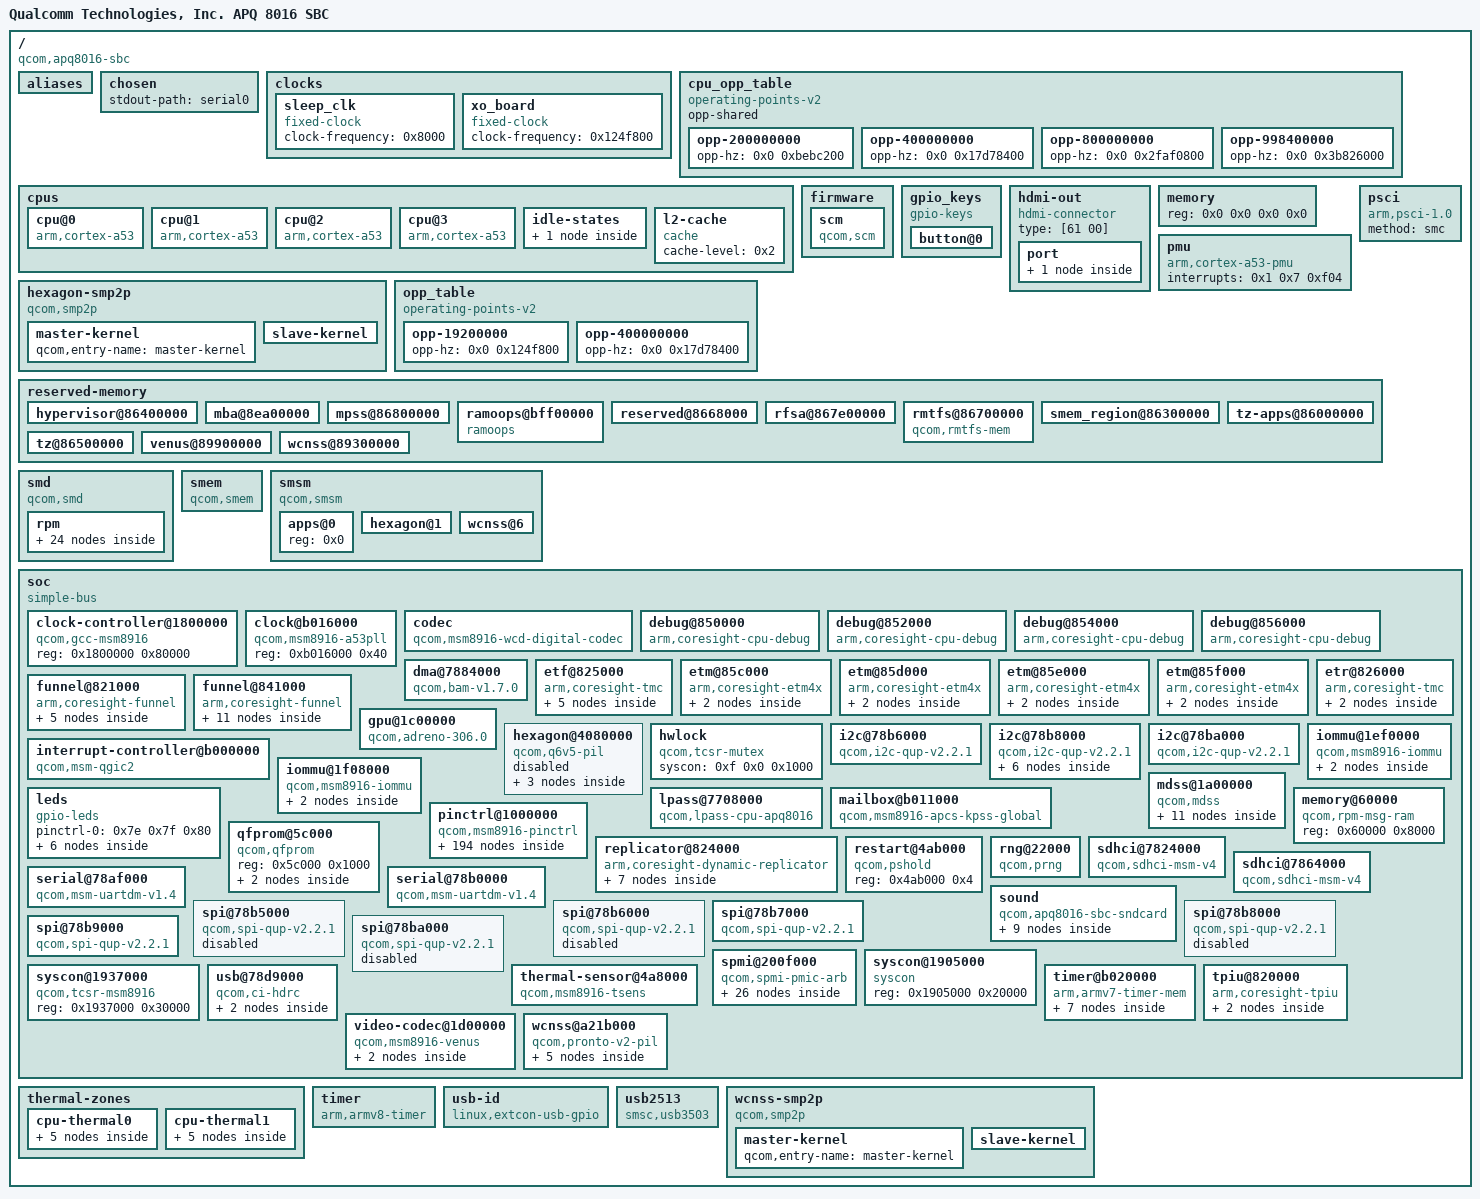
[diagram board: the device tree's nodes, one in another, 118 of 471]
/dts-v1/;

/ {
	#address-cells = <0x2>;
	#size-cells = <0x2>;
	compatible = "qcom,apq8016-sbc", "qcom,apq8016", "qcom,sbc";
	interrupt-parent = <0x1>;
	model = "Qualcomm Technologies, Inc. APQ 8016 SBC";

	__symbols__ {
		CPU0 = "/cpus/cpu@0";
		CPU1 = "/cpus/cpu@1";
		CPU2 = "/cpus/cpu@2";
		CPU3 = "/cpus/cpu@3";
		CPU_SPC = "/cpus/idle-states/spc";
		L2_0 = "/cpus/l2-cache";
		a53pll = "/soc/clock@b016000";
		adv7533_in = "/soc/i2c@78b8000/bridge@39/ports/port@0/endpoint";
		adv7533_int_active = "/soc/pinctrl@1000000/adv533_int_active";
		adv7533_int_suspend = "/soc/pinctrl@1000000/adv7533_int_suspend";
		adv7533_out = "/soc/i2c@78b8000/bridge@39/ports/port@1/endpoint";
		adv7533_switch_active = "/soc/pinctrl@1000000/adv7533_switch_active";
		adv7533_switch_suspend = "/soc/pinctrl@1000000/adv7533_switch_suspend";
		adv_bridge = "/soc/i2c@78b8000/bridge@39";
		apcs = "/soc/mailbox@b011000";
		apps_iommu = "/soc/iommu@1ef0000";
		apps_smsm = "/smsm/apps@0";
		blsp1_uart1 = "/soc/serial@78af000";
		blsp1_uart1_default = "/soc/pinctrl@1000000/blsp1_uart1_default";
		blsp1_uart1_sleep = "/soc/pinctrl@1000000/blsp1_uart1_sleep";
		blsp1_uart2 = "/soc/serial@78b0000";
		blsp1_uart2_default = "/soc/pinctrl@1000000/blsp1_uart2_default";
		blsp1_uart2_sleep = "/soc/pinctrl@1000000/blsp1_uart2_sleep";
		blsp_dma = "/soc/dma@7884000";
		blsp_i2c2 = "/soc/i2c@78b6000";
		blsp_i2c4 = "/soc/i2c@78b8000";
		blsp_i2c6 = "/soc/i2c@78ba000";
		blsp_spi1 = "/soc/spi@78b5000";
		blsp_spi2 = "/soc/spi@78b6000";
		blsp_spi3 = "/soc/spi@78b7000";
		blsp_spi4 = "/soc/spi@78b8000";
		blsp_spi5 = "/soc/spi@78b9000";
		blsp_spi6 = "/soc/spi@78ba000";
		cdc_dmic_lines_act = "/soc/pinctrl@1000000/cdc-dmic-lines/dmic_lines_on";
		cdc_dmic_lines_sus = "/soc/pinctrl@1000000/cdc-dmic-lines/dmic_lines_off";
		cdc_pdm_lines_act = "/soc/pinctrl@1000000/cdc-pdm-lines/pdm_lines_on";
		cdc_pdm_lines_sus = "/soc/pinctrl@1000000/cdc-pdm-lines/pdm_lines_off";
		cpu_alert0 = "/thermal-zones/cpu-thermal0/trips/trip0";
		cpu_alert1 = "/thermal-zones/cpu-thermal1/trips/trip0";
		cpu_crit0 = "/thermal-zones/cpu-thermal0/trips/trip1";
		cpu_crit1 = "/thermal-zones/cpu-thermal1/trips/trip1";
		cpu_opp_table = "/cpu_opp_table";
		dsi0 = "/soc/mdss@1a00000/dsi@1a98000";
		dsi0_in = "/soc/mdss@1a00000/dsi@1a98000/ports/port@0/endpoint";
		dsi0_out = "/soc/mdss@1a00000/dsi@1a98000/ports/port@1/endpoint";
		dsi_phy0 = "/soc/mdss@1a00000/dsi-phy@1a98300";
		etf_in = "/soc/etf@825000/ports/port@0/endpoint";
		etf_out = "/soc/etf@825000/ports/port@1/endpoint";
		etm0_out = "/soc/etm@85c000/port/endpoint";
		etm1_out = "/soc/etm@85d000/port/endpoint";
		etm2_out = "/soc/etm@85e000/port/endpoint";
		etm3_out = "/soc/etm@85f000/port/endpoint";
		etr_in = "/soc/etr@826000/port/endpoint";
		ext_mclk_tlmm_lines_act = "/soc/pinctrl@1000000/ext-mclk-tlmm-lines/mclk_lines_on";
		ext_mclk_tlmm_lines_sus = "/soc/pinctrl@1000000/ext-mclk-tlmm-lines/mclk_lines_off";
		ext_pri_tlmm_lines_act = "/soc/pinctrl@1000000/ext-pri-tlmm-lines/ext_pa_on";
		ext_pri_tlmm_lines_sus = "/soc/pinctrl@1000000/ext-pri-tlmm-lines/ext_pa_off";
		ext_pri_ws_act = "/soc/pinctrl@1000000/ext-pri-ws-line/ext_pa_on";
		ext_pri_ws_sus = "/soc/pinctrl@1000000/ext-pri-ws-line/ext_pa_off";
		ext_sec_tlmm_lines_act = "/soc/pinctrl@1000000/ext-sec-tlmm-lines/tlmm_lines_on";
		ext_sec_tlmm_lines_sus = "/soc/pinctrl@1000000/ext-sec-tlmm-lines/tlmm_lines_off";
		funnel0_in4 = "/soc/funnel@821000/ports/port@4/endpoint";
		funnel0_out = "/soc/funnel@821000/ports/port@8/endpoint";
		funnel1_in0 = "/soc/funnel@841000/ports/port@0/endpoint";
		funnel1_in1 = "/soc/funnel@841000/ports/port@1/endpoint";
		funnel1_in2 = "/soc/funnel@841000/ports/port@2/endpoint";
		funnel1_in3 = "/soc/funnel@841000/ports/port@3/endpoint";
		funnel1_out = "/soc/funnel@841000/ports/port@4/endpoint";
		gcc = "/soc/clock-controller@1800000";
		gpu_iommu = "/soc/iommu@1f08000";
		gpu_opp_table = "/opp_table";
		hdmi_con = "/hdmi-out/port/endpoint";
		hexagon_smp2p_in = "/hexagon-smp2p/slave-kernel";
		hexagon_smp2p_out = "/hexagon-smp2p/master-kernel";
		hexagon_smsm = "/smsm/hexagon@1";
		i2c2_default = "/soc/pinctrl@1000000/i2c2_default";
		i2c2_sleep = "/soc/pinctrl@1000000/i2c2_sleep";
		i2c4_default = "/soc/pinctrl@1000000/i2c4_default";
		i2c4_sleep = "/soc/pinctrl@1000000/i2c4_sleep";
		i2c6_default = "/soc/pinctrl@1000000/i2c6_default";
		i2c6_sleep = "/soc/pinctrl@1000000/i2c6_sleep";
		intc = "/soc/interrupt-controller@b000000";
		lpass = "/soc/lpass@7708000";
		lpass_codec = "/soc/codec";
		ls_exp_gpio_f = "/soc/spmi@200f000/pm8916@0/mpps@a000/pm8916_mpp4";
		mba_mem = "/reserved-memory/mba@8ea00000";
		mdp = "/soc/mdss@1a00000/mdp@1a01000";
		mdp5_intf1_out = "/soc/mdss@1a00000/mdp@1a01000/ports/port@0/endpoint";
		mdss = "/soc/mdss@1a00000";
		mpss_mem = "/reserved-memory/mpss@86800000";
		msm_key_volp_n_default = "/soc/pinctrl@1000000/msm_key_volp_n_default";
		msmgpio = "/soc/pinctrl@1000000";
		msmgpio_leds = "/soc/pinctrl@1000000/msmgpio_leds";
		otg = "/soc/usb@78d9000";
		pm8916_0 = "/soc/spmi@200f000/pm8916@0";
		pm8916_1 = "/soc/spmi@200f000/pm8916@1";
		pm8916_gpios = "/soc/spmi@200f000/pm8916@0/gpios@c000";
		pm8916_gpios_leds = "/soc/spmi@200f000/pm8916@0/gpios@c000/pm8916_gpios_leds";
		pm8916_l1 = "/smd/rpm/rpm_requests/pm8916-regulators/l1";
		pm8916_l10 = "/smd/rpm/rpm_requests/pm8916-regulators/l10";
		pm8916_l11 = "/smd/rpm/rpm_requests/pm8916-regulators/l11";
		pm8916_l12 = "/smd/rpm/rpm_requests/pm8916-regulators/l12";
		pm8916_l13 = "/smd/rpm/rpm_requests/pm8916-regulators/l13";
		pm8916_l14 = "/smd/rpm/rpm_requests/pm8916-regulators/l14";
		pm8916_l15 = "/smd/rpm/rpm_requests/pm8916-regulators/l15";
		pm8916_l16 = "/smd/rpm/rpm_requests/pm8916-regulators/l16";
		pm8916_l17 = "/smd/rpm/rpm_requests/pm8916-regulators/l17";
		pm8916_l18 = "/smd/rpm/rpm_requests/pm8916-regulators/l18";
		pm8916_l2 = "/smd/rpm/rpm_requests/pm8916-regulators/l2";
		pm8916_l3 = "/smd/rpm/rpm_requests/pm8916-regulators/l3";
		pm8916_l4 = "/smd/rpm/rpm_requests/pm8916-regulators/l4";
		pm8916_l5 = "/smd/rpm/rpm_requests/pm8916-regulators/l5";
		pm8916_l6 = "/smd/rpm/rpm_requests/pm8916-regulators/l6";
		pm8916_l7 = "/smd/rpm/rpm_requests/pm8916-regulators/l7";
		pm8916_l8 = "/smd/rpm/rpm_requests/pm8916-regulators/l8";
		pm8916_l9 = "/smd/rpm/rpm_requests/pm8916-regulators/l9";
		pm8916_mpps = "/soc/spmi@200f000/pm8916@0/mpps@a000";
		pm8916_mpps_leds = "/soc/spmi@200f000/pm8916@0/mpps@a000/pm8916_mpps_leds";
		pm8916_s1 = "/smd/rpm/rpm_requests/pm8916-regulators/s1";
		pm8916_s3 = "/smd/rpm/rpm_requests/pm8916-regulators/s3";
		pm8916_s4 = "/smd/rpm/rpm_requests/pm8916-regulators/s4";
		pm8916_temp = "/soc/spmi@200f000/pm8916@0/temp-alarm@2400";
		pm8916_vadc = "/soc/spmi@200f000/pm8916@0/vadc@3100";
		pronto = "/soc/wcnss@a21b000";
		qfprom = "/soc/qfprom@5c000";
		replicator_in = "/soc/replicator@824000/ports/port@2/endpoint";
		replicator_out0 = "/soc/replicator@824000/ports/port@0/endpoint";
		replicator_out1 = "/soc/replicator@824000/ports/port@1/endpoint";
		rpm_msg_ram = "/soc/memory@60000";
		rpmcc = "/smd/rpm/rpm_requests/qcom,rpmcc";
		scm = "/firmware/scm";
		sdc1_clk_off = "/soc/pinctrl@1000000/pmx_sdc1_clk/clk_off";
		sdc1_clk_on = "/soc/pinctrl@1000000/pmx_sdc1_clk/clk_on";
		sdc1_cmd_off = "/soc/pinctrl@1000000/pmx_sdc1_cmd/cmd_off";
		sdc1_cmd_on = "/soc/pinctrl@1000000/pmx_sdc1_cmd/cmd_on";
		sdc1_data_off = "/soc/pinctrl@1000000/pmx_sdc1_data/data_off";
		sdc1_data_on = "/soc/pinctrl@1000000/pmx_sdc1_data/data_on";
		sdc2_cd_off = "/soc/pinctrl@1000000/pmx_sdc2_cd_pin/cd_off";
		sdc2_cd_on = "/soc/pinctrl@1000000/pmx_sdc2_cd_pin/cd_on";
		sdc2_clk_off = "/soc/pinctrl@1000000/pmx_sdc2_clk/clk_off";
		sdc2_clk_on = "/soc/pinctrl@1000000/pmx_sdc2_clk/clk_on";
		sdc2_cmd_off = "/soc/pinctrl@1000000/pmx_sdc2_cmd/cmd_off";
		sdc2_cmd_on = "/soc/pinctrl@1000000/pmx_sdc2_cmd/cmd_on";
		sdc2_data_off = "/soc/pinctrl@1000000/pmx_sdc2_data/data_off";
		sdc2_data_on = "/soc/pinctrl@1000000/pmx_sdc2_data/data_on";
		sdhc_1 = "/soc/sdhci@7824000";
		sdhc_2 = "/soc/sdhci@7864000";
		sleep_clk = "/clocks/sleep_clk";
		smd_rpm_regulators = "/smd/rpm/rpm_requests/pm8916-regulators";
		smem_mem = "/reserved-memory/smem_region@86300000";
		soc = "/soc";
		sound = "/soc/sound";
		spi1_default = "/soc/pinctrl@1000000/spi1_default";
		spi1_sleep = "/soc/pinctrl@1000000/spi1_sleep";
		spi2_default = "/soc/pinctrl@1000000/spi2_default";
		spi2_sleep = "/soc/pinctrl@1000000/spi2_sleep";
		spi3_default = "/soc/pinctrl@1000000/spi3_default";
		spi3_sleep = "/soc/pinctrl@1000000/spi3_sleep";
		spi4_default = "/soc/pinctrl@1000000/spi4_default";
		spi4_sleep = "/soc/pinctrl@1000000/spi4_sleep";
		spi5_default = "/soc/pinctrl@1000000/spi5_default";
		spi5_sleep = "/soc/pinctrl@1000000/spi5_sleep";
		spi6_default = "/soc/pinctrl@1000000/spi6_default";
		spi6_sleep = "/soc/pinctrl@1000000/spi6_sleep";
		spmi_bus = "/soc/spmi@200f000";
		tcsr = "/soc/syscon@1937000";
		tcsr_mutex = "/soc/hwlock";
		tcsr_mutex_regs = "/soc/syscon@1905000";
		tpiu_in = "/soc/tpiu@820000/port/endpoint";
		tsens = "/soc/thermal-sensor@4a8000";
		tsens_caldata = "/soc/qfprom@5c000/caldata@d0";
		tsens_calsel = "/soc/qfprom@5c000/calsel@ec";
		usb_hs_phy = "/soc/usb@78d9000/ulpi/phy";
		usb_hub_reset_pm = "/soc/spmi@200f000/pm8916@0/gpios@c000/usb_hub_reset_pm";
		usb_id = "/usb-id";
		usb_id_default = "/soc/pinctrl@1000000/usb-id-default";
		usb_sw_sel_pm = "/soc/spmi@200f000/pm8916@0/gpios@c000/usb_sw_sel_pm";
		venus = "/soc/video-codec@1d00000";
		venus_mem = "/reserved-memory/venus@89900000";
		wcd_codec = "/soc/spmi@200f000/pm8916@1/codec@f000";
		wcnss_mem = "/reserved-memory/wcnss@89300000";
		wcnss_pin_a = "/soc/pinctrl@1000000/wcnss-active";
		wcnss_smp2p_in = "/wcnss-smp2p/slave-kernel";
		wcnss_smp2p_out = "/wcnss-smp2p/master-kernel";
		wcnss_smsm = "/smsm/wcnss@6";
		xo_board = "/clocks/xo_board";
	};

	aliases {
		i2c0 = "/soc/i2c@78b6000";
		i2c1 = "/soc/i2c@78ba000";
		i2c3 = "/soc/i2c@78b8000";
		sdhc1 = "/soc/sdhci@7824000";
		sdhc2 = "/soc/sdhci@7864000";
		serial0 = "/soc/serial@78b0000";
		serial1 = "/soc/serial@78af000";
		spi0 = "/soc/spi@78b9000";
		spi1 = "/soc/spi@78b7000";
		usid0 = "/soc/spmi@200f000/pm8916@0";
	};

	chosen {
		stdout-path = "serial0";
	};

	clocks {

		sleep_clk {
			#clock-cells = <0x0>;
			clock-frequency = <0x8000>;
			compatible = "fixed-clock";
			linux,phandle = <0x93>;
			phandle = <0x93>;
		};

		xo_board {
			#clock-cells = <0x0>;
			clock-frequency = <0x124f800>;
			compatible = "fixed-clock";
			linux,phandle = <0x32>;
			phandle = <0x32>;
		};
	};

	cpu_opp_table {
		compatible = "operating-points-v2";
		linux,phandle = <0x5>;
		opp-shared;
		phandle = <0x5>;

		opp-200000000 {
			opp-hz = <0x0 0xbebc200>;
		};

		opp-400000000 {
			opp-hz = <0x0 0x17d78400>;
		};

		opp-800000000 {
			opp-hz = <0x0 0x2faf0800>;
		};

		opp-998400000 {
			opp-hz = <0x0 0x3b826000>;
		};
	};

	cpus {
		#address-cells = <0x1>;
		#size-cells = <0x0>;

		cpu@0 {
			#cooling-cells = <0x2>;
			clocks = <0x4>;
			compatible = "arm,cortex-a53", "arm,armv8";
			cpu-idle-states = <0x3>;
			device_type = "cpu";
			enable-method = "psci";
			linux,phandle = <0x8>;
			next-level-cache = <0x2>;
			operating-points-v2 = <0x5>;
			phandle = <0x8>;
			reg = <0x0>;
		};

		cpu@1 {
			#cooling-cells = <0x2>;
			clocks = <0x4>;
			compatible = "arm,cortex-a53", "arm,armv8";
			cpu-idle-states = <0x3>;
			device_type = "cpu";
			enable-method = "psci";
			linux,phandle = <0x76>;
			next-level-cache = <0x2>;
			operating-points-v2 = <0x5>;
			phandle = <0x76>;
			reg = <0x1>;
		};

		cpu@2 {
			#cooling-cells = <0x2>;
			clocks = <0x4>;
			compatible = "arm,cortex-a53", "arm,armv8";
			cpu-idle-states = <0x3>;
			device_type = "cpu";
			enable-method = "psci";
			linux,phandle = <0x77>;
			next-level-cache = <0x2>;
			operating-points-v2 = <0x5>;
			phandle = <0x77>;
			reg = <0x2>;
		};

		cpu@3 {
			#cooling-cells = <0x2>;
			clocks = <0x4>;
			compatible = "arm,cortex-a53", "arm,armv8";
			cpu-idle-states = <0x3>;
			device_type = "cpu";
			enable-method = "psci";
			linux,phandle = <0x78>;
			next-level-cache = <0x2>;
			operating-points-v2 = <0x5>;
			phandle = <0x78>;
			reg = <0x3>;
		};

		idle-states {

			spc {
				arm,psci-suspend-param = <0x40000002>;
				compatible = "arm,idle-state";
				entry-latency-us = <0x82>;
				exit-latency-us = <0x96>;
				linux,phandle = <0x3>;
				local-timer-stop;
				min-residency-us = <0x7d0>;
				phandle = <0x3>;
			};
		};

		l2-cache {
			cache-level = <0x2>;
			compatible = "cache";
			linux,phandle = <0x2>;
			phandle = <0x2>;
		};
	};

	firmware {

		scm {
			#reset-cells = <0x1>;
			clock-names = "core", "bus", "iface";
			clocks = <0xd 0x68 0xd 0x67 0xd 0x66>;
			compatible = "qcom,scm";
			linux,phandle = <0x5b>;
			phandle = <0x5b>;
			qcom,dload-mode = <0xe 0x6100>;
		};
	};

	gpio_keys {
		#address-cells = <0x1>;
		#size-cells = <0x0>;
		autorepeat;
		compatible = "gpio-keys";
		pinctrl-0 = <0x90>;
		pinctrl-names = "default";

		button@0 {
			gpios = <0x26 0x6b 0x1>;
			label = "Volume Up";
			linux,code = <0x73>;
		};
	};

	hdmi-out {
		compatible = "hdmi-connector";
		type = [61 00];

		port {

			endpoint {
				linux,phandle = <0x2f>;
				phandle = <0x2f>;
				remote-endpoint = <0x8f>;
			};
		};
	};

	hexagon-smp2p {
		compatible = "qcom,smp2p";
		interrupts = <0x0 0x1b 0x1>;
		qcom,ipc = <0x4 0x8 0xe>;
		qcom,local-pid = <0x0>;
		qcom,remote-pid = <0x1>;
		qcom,smem = <0x1b3 0x1ac>;

		master-kernel {
			#qcom,smem-state-cells = <0x1>;
			linux,phandle = <0x5a>;
			phandle = <0x5a>;
			qcom,entry-name = "master-kernel";
		};

		slave-kernel {
			#interrupt-cells = <0x2>;
			interrupt-controller;
			linux,phandle = <0x59>;
			phandle = <0x59>;
			qcom,entry-name = "slave-kernel";
		};
	};

	memory {
		device_type = "memory";
		reg = <0x0 0x0 0x0 0x0>;
	};

	opp_table {
		compatible = "operating-points-v2";
		linux,phandle = <0x50>;
		phandle = <0x50>;

		opp-19200000 {
			opp-hz = <0x0 0x124f800>;
		};

		opp-400000000 {
			opp-hz = <0x0 0x17d78400>;
		};
	};

	pmu {
		compatible = "arm,cortex-a53-pmu";
		interrupts = <0x1 0x7 0xf04>;
	};

	psci {
		compatible = "arm,psci-1.0";
		method = "smc";
	};

	reserved-memory {
		#address-cells = <0x2>;
		#size-cells = <0x2>;
		ranges;

		hypervisor@86400000 {
			no-map;
			reg = <0x0 0x86400000 0x0 0x100000>;
		};

		mba@8ea00000 {
			linux,phandle = <0x5e>;
			no-map;
			phandle = <0x5e>;
			reg = <0x0 0x8ea00000 0x0 0x100000>;
		};

		mpss@86800000 {
			linux,phandle = <0x5f>;
			no-map;
			phandle = <0x5f>;
			reg = <0x0 0x86800000 0x0 0x2b00000>;
		};

		ramoops@bff00000 {
			compatible = "ramoops";
			console-size = <0x20000>;
			ftrace-size = <0x20000>;
			record-size = <0x20000>;
			reg = <0x0 0xbff00000 0x0 0x100000>;
		};

		reserved@8668000 {
			no-map;
			reg = <0x0 0x86680000 0x0 0x80000>;
		};

		rfsa@867e00000 {
			no-map;
			reg = <0x0 0x867e0000 0x0 0x20000>;
		};

		rmtfs@86700000 {
			compatible = "qcom,rmtfs-mem";
			no-map;
			qcom,client-id = <0x1>;
			reg = <0x0 0x86700000 0x0 0xe0000>;
		};

		smem_region@86300000 {
			linux,phandle = <0xa>;
			no-map;
			phandle = <0xa>;
			reg = <0x0 0x86300000 0x0 0x100000>;
		};

		tz-apps@86000000 {
			no-map;
			reg = <0x0 0x86000000 0x0 0x300000>;
		};

		tz@86500000 {
			no-map;
			reg = <0x0 0x86500000 0x0 0x180000>;
		};

		venus@89900000 {
			linux,phandle = <0x7d>;
			no-map;
			phandle = <0x7d>;
			reg = <0x0 0x89900000 0x0 0x600000>;
		};

		wcnss@89300000 {
			linux,phandle = <0x60>;
			no-map;
			phandle = <0x60>;
			reg = <0x0 0x89300000 0x0 0x600000>;
		};
	};

	smd {
		compatible = "qcom,smd";

		rpm {
			interrupts = <0x0 0xa8 0x1>;
			qcom,ipc = <0x4 0x8 0x0>;
			qcom,smd-edge = <0xf>;

			rpm_requests {
				compatible = "qcom,rpm-msm8916";
				qcom,smd-channels = "rpm_requests";

				pm8916-regulators {
					compatible = "qcom,rpm-pm8916-regulators";
					linux,phandle = <0xb1>;
					phandle = <0xb1>;
					vdd_l1_l2_l3-supply = <0x64>;
					vdd_l4_l5_l6-supply = <0x8d>;
					vdd_l5-supply = <0x64>;
					vdd_l7-supply = <0x8d>;

					l1 {
						linux,phandle = <0xb2>;
						phandle = <0xb2>;
						regulator-max-microvolt = <0x174508>;
						regulator-min-microvolt = <0x5b8d8>;
					};

					l10 {
						linux,phandle = <0xb4>;
						phandle = <0xb4>;
						regulator-max-microvolt = <0x32eb28>;
						regulator-min-microvolt = <0x1ab3f0>;
					};

					l11 {
						linux,phandle = <0x3b>;
						phandle = <0x3b>;
						regulator-allow-set-load;
						regulator-max-microvolt = <0x32eb28>;
						regulator-min-microvolt = <0x1ab3f0>;
						regulator-system-load = <0x30d40>;
					};

					l12 {
						linux,phandle = <0x3c>;
						phandle = <0x3c>;
						regulator-max-microvolt = <0x32eb28>;
						regulator-min-microvolt = <0x1ab3f0>;
					};

					l13 {
						linux,phandle = <0x4a>;
						phandle = <0x4a>;
						regulator-max-microvolt = <0x32eb28>;
						regulator-min-microvolt = <0x1ab3f0>;
					};

					l14 {
						linux,phandle = <0xb5>;
						phandle = <0xb5>;
						regulator-max-microvolt = <0x32eb28>;
						regulator-min-microvolt = <0x1ab3f0>;
					};

					l15 {
						linux,phandle = <0xb6>;
						phandle = <0xb6>;
						regulator-always-on;
						regulator-max-microvolt = <0x32eb28>;
						regulator-min-microvolt = <0x1ab3f0>;
					};

					l16 {
						linux,phandle = <0xb7>;
						phandle = <0xb7>;
						regulator-max-microvolt = <0x32eb28>;
						regulator-min-microvolt = <0x1ab3f0>;
					};

					l17 {
						linux,phandle = <0x29>;
						phandle = <0x29>;
						regulator-max-microvolt = <0x325aa0>;
						regulator-min-microvolt = <0x325aa0>;
					};

					l18 {
						linux,phandle = <0xb8>;
						phandle = <0xb8>;
						regulator-max-microvolt = <0x32eb28>;
						regulator-min-microvolt = <0x1ab3f0>;
					};

					l2 {
						linux,phandle = <0x56>;
						phandle = <0x56>;
						regulator-max-microvolt = <0x124f80>;
						regulator-min-microvolt = <0x124f80>;
					};

					l3 {
						linux,phandle = <0x5d>;
						phandle = <0x5d>;
						regulator-max-microvolt = <0x174508>;
						regulator-min-microvolt = <0x5b8d8>;
					};

					l4 {
						linux,phandle = <0xb3>;
						phandle = <0xb3>;
						regulator-max-microvolt = <0x32eb28>;
						regulator-min-microvolt = <0x1ab3f0>;
					};

					l5 {
						linux,phandle = <0x34>;
						phandle = <0x34>;
						regulator-max-microvolt = <0x32eb28>;
						regulator-min-microvolt = <0x1ab3f0>;
					};

					l6 {
						linux,phandle = <0x28>;
						phandle = <0x28>;
						regulator-max-microvolt = <0x1b7740>;
						regulator-min-microvolt = <0x1b7740>;
					};

					l7 {
						linux,phandle = <0x49>;
						phandle = <0x49>;
						regulator-max-microvolt = <0x32eb28>;
						regulator-min-microvolt = <0x1ab3f0>;
					};

					l8 {
						linux,phandle = <0x33>;
						phandle = <0x33>;
						regulator-max-microvolt = <0x32eb28>;
						regulator-min-microvolt = <0x1ab3f0>;
					};

					l9 {
						linux,phandle = <0x65>;
						phandle = <0x65>;
						regulator-max-microvolt = <0x32eb28>;
						regulator-min-microvolt = <0x1ab3f0>;
					};

					s1 {
						linux,phandle = <0x5c>;
						phandle = <0x5c>;
						regulator-max-microvolt = <0x17d590>;
						regulator-min-microvolt = <0x5b8d8>;
					};

					s3 {
						linux,phandle = <0x64>;
						phandle = <0x64>;
						regulator-max-microvolt = <0x17d590>;
						regulator-min-microvolt = <0x5b8d8>;
					};

					s4 {
						linux,phandle = <0x8d>;
						phandle = <0x8d>;
						regulator-always-on;
						regulator-boot-on;
						regulator-max-microvolt = <0x1b7740>;
						regulator-min-microvolt = <0x1b7740>;
					};
				};

				qcom,rpmcc {
					#clock-cells = <0x1>;
					compatible = "qcom,rpmcc-msm8916";
					linux,phandle = <0x27>;
					phandle = <0x27>;
				};
			};
		};
	};

	smem {
		compatible = "qcom,smem";
		hwlocks = <0xc 0x3>;
		memory-region = <0xa>;
		qcom,rpm-msg-ram = <0xb>;
	};

	smsm {
		#address-cells = <0x1>;
		#size-cells = <0x0>;
		compatible = "qcom,smsm";
		qcom,ipc-1 = <0x4 0x8 0xd>;
		qcom,ipc-3 = <0x4 0x8 0x13>;

		apps@0 {
			#qcom,smem-state-cells = <0x1>;
			linux,phandle = <0x67>;
			phandle = <0x67>;
			reg = <0x0>;
		};

		hexagon@1 {
			#interrupt-cells = <0x2>;
			interrupt-controller;
			interrupts = <0x0 0x1a 0x1>;
			linux,phandle = <0xb9>;
			phandle = <0xb9>;
			reg = <0x1>;
		};

		wcnss@6 {
			#interrupt-cells = <0x2>;
			interrupt-controller;
			interrupts = <0x0 0x90 0x1>;
			linux,phandle = <0xba>;
			phandle = <0xba>;
			reg = <0x6>;
		};
	};

	soc {
		#address-cells = <0x1>;
		#size-cells = <0x1>;
		compatible = "simple-bus";
		linux,phandle = <0x94>;
		phandle = <0x94>;
		ranges = <0x0 0x0 0x0 0xffffffff>;

		clock-controller@1800000 {
			#clock-cells = <0x1>;
			#power-domain-cells = <0x1>;
			#reset-cells = <0x1>;
			compatible = "qcom,gcc-msm8916";
			linux,phandle = <0xd>;
			phandle = <0xd>;
			reg = <0x1800000 0x80000>;
		};

		clock@b016000 {
			#clock-cells = <0x0>;
			compatible = "qcom,msm8916-a53pll";
			linux,phandle = <0x13>;
			phandle = <0x13>;
			reg = <0xb016000 0x40>;
		};

		codec {
			#sound-dai-cells = <0x1>;
			clock-names = "ahbix-clk", "mclk";
			clocks = <0xd 0x9a 0xd 0x9f>;
			compatible = "qcom,msm8916-wcd-digital-codec";
			linux,phandle = <0x8b>;
			phandle = <0x8b>;
			reg = <0x771c000 0x400>;
			status = "okay";
		};

		debug@850000 {
			clock-names = "apb_pclk";
			clocks = <0x27 0x8>;
			compatible = "arm,coresight-cpu-debug", "arm,primecell";
			cpu = <0x8>;
			reg = <0x850000 0x1000>;
		};

		debug@852000 {
			clock-names = "apb_pclk";
			clocks = <0x27 0x8>;
			compatible = "arm,coresight-cpu-debug", "arm,primecell";
			cpu = <0x76>;
			reg = <0x852000 0x1000>;
		};

		debug@854000 {
			clock-names = "apb_pclk";
			clocks = <0x27 0x8>;
			compatible = "arm,coresight-cpu-debug", "arm,primecell";
			cpu = <0x77>;
			reg = <0x854000 0x1000>;
		};

		debug@856000 {
			clock-names = "apb_pclk";
			clocks = <0x27 0x8>;
			compatible = "arm,coresight-cpu-debug", "arm,primecell";
			cpu = <0x78>;
			reg = <0x856000 0x1000>;
		};

		dma@7884000 {
			#dma-cells = <0x1>;
			clock-names = "bam_clk";
			clocks = <0xd 0x36>;
			compatible = "qcom,bam-v1.7.0";
			interrupts = <0x0 0xee 0x4>;
			linux,phandle = <0x10>;
			phandle = <0x10>;
			qcom,ee = <0x0>;
			reg = <0x7884000 0x23000>;
			status = "okay";
		};

		etf@825000 {
			clock-names = "apb_pclk", "atclk";
			clocks = <0x27 0x8 0x27 0x9>;
			compatible = "arm,coresight-tmc", "arm,primecell";
			reg = <0x825000 0x1000>;

			ports {
				#address-cells = <0x1>;
				#size-cells = <0x0>;

				port@0 {
					reg = <0x0>;

					endpoint {
						linux,phandle = <0x6a>;
						phandle = <0x6a>;
						remote-endpoint = <0x6e>;
						slave-mode;
					};
				};

				port@1 {
					reg = <0x0>;

					endpoint {
						linux,phandle = <0x6d>;
						phandle = <0x6d>;
						remote-endpoint = <0x6f>;
					};
				};
			};
		};

		etm@85c000 {
			clock-names = "apb_pclk", "atclk";
			clocks = <0x27 0x8 0x27 0x9>;
			compatible = "arm,coresight-etm4x", "arm,primecell";
			cpu = <0x8>;
			reg = <0x85c000 0x1000>;

			port {

				endpoint {
					linux,phandle = <0x71>;
					phandle = <0x71>;
					remote-endpoint = <0x79>;
				};
			};
		};

		etm@85d000 {
			clock-names = "apb_pclk", "atclk";
			clocks = <0x27 0x8 0x27 0x9>;
			compatible = "arm,coresight-etm4x", "arm,primecell";
			cpu = <0x76>;
			reg = <0x85d000 0x1000>;

			port {

				endpoint {
					linux,phandle = <0x72>;
					phandle = <0x72>;
					remote-endpoint = <0x7a>;
				};
			};
		};

		etm@85e000 {
			clock-names = "apb_pclk", "atclk";
			clocks = <0x27 0x8 0x27 0x9>;
			compatible = "arm,coresight-etm4x", "arm,primecell";
			cpu = <0x77>;
			reg = <0x85e000 0x1000>;

			port {

				endpoint {
					linux,phandle = <0x73>;
					phandle = <0x73>;
					remote-endpoint = <0x7b>;
				};
			};
		};

		etm@85f000 {
			clock-names = "apb_pclk", "atclk";
			clocks = <0x27 0x8 0x27 0x9>;
			compatible = "arm,coresight-etm4x", "arm,primecell";
			cpu = <0x78>;
			reg = <0x85f000 0x1000>;

			port {

				endpoint {
					linux,phandle = <0x74>;
					phandle = <0x74>;
					remote-endpoint = <0x7c>;
				};
			};
		};

		etr@826000 {
			clock-names = "apb_pclk", "atclk";
			clocks = <0x27 0x8 0x27 0x9>;
			compatible = "arm,coresight-tmc", "arm,primecell";
			reg = <0x826000 0x1000>;

			port {

				endpoint {
					linux,phandle = <0x6b>;
					phandle = <0x6b>;
					remote-endpoint = <0x70>;
					slave-mode;
				};
			};
		};

		funnel@821000 {
			clock-names = "apb_pclk", "atclk";
			clocks = <0x27 0x8 0x27 0x9>;
			compatible = "arm,coresight-funnel", "arm,primecell";
			reg = <0x821000 0x1000>;

			ports {
				#address-cells = <0x1>;
				#size-cells = <0x0>;

				port@4 {
					reg = <0x4>;

					endpoint {
						linux,phandle = <0x75>;
						phandle = <0x75>;
						remote-endpoint = <0x69>;
						slave-mode;
					};
				};

				port@8 {
					reg = <0x0>;

					endpoint {
						linux,phandle = <0x6e>;
						phandle = <0x6e>;
						remote-endpoint = <0x6a>;
					};
				};
			};
		};

		funnel@841000 {
			clock-names = "apb_pclk", "atclk";
			clocks = <0x27 0x8 0x27 0x9>;
			compatible = "arm,coresight-funnel", "arm,primecell";
			reg = <0x841000 0x1000>;

			ports {
				#address-cells = <0x1>;
				#size-cells = <0x0>;

				port@0 {
					reg = <0x0>;

					endpoint {
						linux,phandle = <0x79>;
						phandle = <0x79>;
						remote-endpoint = <0x71>;
						slave-mode;
					};
				};

				port@1 {
					reg = <0x1>;

					endpoint {
						linux,phandle = <0x7a>;
						phandle = <0x7a>;
						remote-endpoint = <0x72>;
						slave-mode;
					};
				};

				port@2 {
					reg = <0x2>;

					endpoint {
						linux,phandle = <0x7b>;
						phandle = <0x7b>;
						remote-endpoint = <0x73>;
						slave-mode;
					};
				};

				port@3 {
					reg = <0x3>;

					endpoint {
						linux,phandle = <0x7c>;
						phandle = <0x7c>;
						remote-endpoint = <0x74>;
						slave-mode;
					};
				};

				port@4 {
					reg = <0x0>;

					endpoint {
						linux,phandle = <0x69>;
						phandle = <0x69>;
						remote-endpoint = <0x75>;
					};
				};
			};
		};

		gpu@1c00000 {
			clock-names = "core", "iface", "mem", "mem_iface", "alt_mem_iface", "gfx3d";
			clocks = <0xd 0x76 0xd 0x75 0xd 0x69 0xd 0x8e 0xd 0x8f 0xd 0xe>;
			compatible = "qcom,adreno-306.0", "qcom,adreno";
			interrupt-names = "kgsl_3d0_irq";
			interrupts = <0x0 0x21 0x4>;
			iommus = <0x51 0x1 0x51 0x2>;
			operating-points-v2 = <0x50>;
			power-domains = <0xd 0x5>;
			reg = <0x1c00000 0x20000>;
			reg-names = "kgsl_3d0_reg_memory";
		};

		hexagon@4080000 {
			clock-names = "iface", "bus", "mem", "xo";
			clocks = <0xd 0x74 0xd 0xa0 0xd 0x46 0x32>;
			compatible = "qcom,q6v5-pil";
			cx-supply = <0x5c>;
			interrupt-names = "wdog", "fatal", "ready", "handover", "stop-ack";
			interrupts-extended = <0x1 0x0 0x18 0x1 0x59 0x0 0x0 0x59 0x1 0x0 0x59 0x2 0x0 0x59 0x3 0x0>;
			mx-supply = <0x5d>;
			pll-supply = <0x49>;
			qcom,halt-regs = <0xe 0x18000 0x19000 0x1a000>;
			qcom,smem-state-names = "stop";
			qcom,smem-states = <0x5a 0x0>;
			reg = <0x4080000 0x100 0x4020000 0x40>;
			reg-names = "qdsp6", "rmb";
			reset-names = "mss_restart";
			resets = <0x5b 0x0>;
			status = "disabled";

			mba {
				memory-region = <0x5e>;
			};

			mpss {
				memory-region = <0x5f>;
			};

			smd-edge {
				interrupts = <0x0 0x19 0x1>;
				label = "hexagon";
				qcom,ipc = <0x4 0x8 0xc>;
				qcom,remote-pid = <0x1>;
				qcom,smd-edge = <0x0>;
			};
		};

		hwlock {
			#hwlock-cells = <0x1>;
			compatible = "qcom,tcsr-mutex";
			linux,phandle = <0xc>;
			phandle = <0xc>;
			syscon = <0xf 0x0 0x1000>;
		};

		i2c@78b6000 {
			#address-cells = <0x1>;
			#size-cells = <0x0>;
			clock-names = "iface", "core";
			clocks = <0xd 0x36 0xd 0x3a>;
			compatible = "qcom,i2c-qup-v2.2.1";
			interrupts = <0x0 0x60 0x4>;
			label = "LS-I2C0";
			linux,phandle = <0xa3>;
			phandle = <0xa3>;
			pinctrl-0 = <0x22>;
			pinctrl-1 = <0x23>;
			pinctrl-names = "default", "sleep";
			reg = <0x78b6000 0x500>;
			status = "okay";
		};

		i2c@78b8000 {
			#address-cells = <0x1>;
			#size-cells = <0x0>;
			clock-names = "iface", "core";
			clocks = <0xd 0x36 0xd 0x3e>;
			compatible = "qcom,i2c-qup-v2.2.1";
			interrupts = <0x0 0x62 0x4>;
			label = "HS-I2C2";
			linux,phandle = <0xa4>;
			phandle = <0xa4>;
			pinctrl-0 = <0x24>;
			pinctrl-1 = <0x25>;
			pinctrl-names = "default", "sleep";
			reg = <0x78b8000 0x500>;
			status = "okay";

			bridge@39 {
				#sound-dai-cells = <0x1>;
				adi,dsi-lanes = <0x4>;
				avdd-supply = <0x28>;
				clock-names = "cec";
				clocks = <0x27 0x18>;
				compatible = "adi,adv7533";
				interrupt-parent = <0x26>;
				interrupts = <0x1f 0x2>;
				linux,phandle = <0x8a>;
				pd-gpios = <0x26 0x20 0x0>;
				phandle = <0x8a>;
				pinctrl-0 = <0x2a 0x2b>;
				pinctrl-1 = <0x2c 0x2d>;
				pinctrl-names = "default", "sleep";
				reg = <0x39>;
				status = "okay";
				v1p2-supply = <0x28>;
				v3p3-supply = <0x29>;

				ports {
					#address-cells = <0x1>;
					#size-cells = <0x0>;

					port@0 {
						reg = <0x0>;

						endpoint {
							linux,phandle = <0x58>;
							phandle = <0x58>;
							remote-endpoint = <0x2e>;
						};
					};

					port@1 {
						reg = <0x1>;

						endpoint {
							linux,phandle = <0x8f>;
							phandle = <0x8f>;
							remote-endpoint = <0x2f>;
						};
					};
				};
			};
		};

		i2c@78ba000 {
			#address-cells = <0x1>;
			#size-cells = <0x0>;
			clock-names = "iface", "core";
			clocks = <0xd 0x36 0xd 0x42>;
			compatible = "qcom,i2c-qup-v2.2.1";
			interrupts = <0x0 0x64 0x4>;
			label = "LS-I2C1";
			linux,phandle = <0xa5>;
			phandle = <0xa5>;
			pinctrl-0 = <0x30>;
			pinctrl-1 = <0x31>;
			pinctrl-names = "default", "sleep";
			reg = <0x78ba000 0x500>;
			status = "okay";
		};

		interrupt-controller@b000000 {
			#interrupt-cells = <0x3>;
			compatible = "qcom,msm-qgic2";
			interrupt-controller;
			linux,phandle = <0x1>;
			phandle = <0x1>;
			reg = <0xb000000 0x1000 0xb002000 0x1000>;
		};

		iommu@1ef0000 {
			#address-cells = <0x1>;
			#iommu-cells = <0x1>;
			#size-cells = <0x1>;
			clock-names = "iface", "bus";
			clocks = <0xd 0x81 0xd 0x8b>;
			compatible = "qcom,msm8916-iommu", "qcom,msm-iommu-v1";
			linux,phandle = <0x53>;
			phandle = <0x53>;
			qcom,iommu-secure-id = <0x11>;
			ranges = <0x0 0x1e20000 0x40000>;
			reg = <0x1ef0000 0x3000>;

			iommu-ctx@4000 {
				compatible = "qcom,msm-iommu-v1-ns";
				interrupts = <0x0 0x46 0x4>;
				reg = <0x4000 0x1000>;
			};

			iommu-ctx@5000 {
				compatible = "qcom,msm-iommu-v1-sec";
				interrupts = <0x0 0x46 0x4>;
				reg = <0x5000 0x1000>;
			};
		};

		iommu@1f08000 {
			#address-cells = <0x1>;
			#iommu-cells = <0x1>;
			#size-cells = <0x1>;
			clock-names = "iface", "bus";
			clocks = <0xd 0x81 0xd 0x8c>;
			compatible = "qcom,msm8916-iommu", "qcom,msm-iommu-v1";
			linux,phandle = <0x51>;
			phandle = <0x51>;
			qcom,iommu-secure-id = <0x12>;
			ranges = <0x0 0x1f08000 0x10000>;

			iommu-ctx@1000 {
				compatible = "qcom,msm-iommu-v1-ns";
				interrupts = <0x0 0xf1 0x4>;
				reg = <0x1000 0x1000>;
			};

			iommu-ctx@2000 {
				compatible = "qcom,msm-iommu-v1-ns";
				interrupts = <0x0 0xf2 0x4>;
				reg = <0x2000 0x1000>;
			};
		};

		leds {
			compatible = "gpio-leds";
			pinctrl-0 = <0x7e 0x7f 0x80>;
			pinctrl-names = "default";

			led@1 {
				default-state = "off";
				gpios = <0x26 0x15 0x0>;
				label = "apq8016-sbc:green:user1";
				linux,default-trigger = "heartbeat";
			};

			led@2 {
				default-state = "off";
				gpios = <0x26 0x78 0x0>;
				label = "apq8016-sbc:green:user2";
				linux,default-trigger = "mmc0";
			};

			led@3 {
				default-state = "off";
				gpios = <0x81 0x1 0x0>;
				label = "apq8016-sbc:green:user3";
				linux,default-trigger = "mmc1";
			};

			led@4 {
				default-state = "off";
				gpios = <0x81 0x2 0x0>;
				label = "apq8016-sbc:green:user4";
				linux,default-trigger = "none";
				panic-indicator;
			};

			led@5 {
				default-state = "off";
				gpios = <0x82 0x2 0x0>;
				label = "apq8016-sbc:yellow:wlan";
				linux,default-trigger = "phy0tx";
			};

			led@6 {
				default-state = "off";
				gpios = <0x82 0x3 0x0>;
				label = "apq8016-sbc:blue:bt";
				linux,default-trigger = "bluetooth-power";
			};
		};

		lpass@7708000 {
			#sound-dai-cells = <0x1>;
			clock-names = "ahbix-clk", "pcnoc-mport-clk", "pcnoc-sway-clk", "mi2s-bit-clk0", "mi2s-bit-clk1", "mi2s-bit-clk2", "mi2s-bit-clk3";
			clocks = <0xd 0x9a 0xd 0x96 0xd 0x97 0xd 0x9c 0xd 0x9d 0xd 0x9d 0xd 0x9e>;
			compatible = "qcom,lpass-cpu-apq8016";
			interrupt-names = "lpass-irq-lpaif";
			interrupts = <0x0 0xa0 0x4>;
			linux,phandle = <0x89>;
			phandle = <0x89>;
			reg = <0x7708000 0x10000>;
			reg-names = "lpass-lpaif";
			status = "okay";
		};

		mailbox@b011000 {
			#clock-cells = <0x0>;
			#mbox-cells = <0x1>;
			clocks = <0x13>;
			compatible = "qcom,msm8916-apcs-kpss-global", "syscon";
			linux,phandle = <0x4>;
			phandle = <0x4>;
			reg = <0xb011000 0x1000>;
		};

		mdss@1a00000 {
			#address-cells = <0x1>;
			#interrupt-cells = <0x1>;
			#size-cells = <0x1>;
			clock-names = "iface", "bus", "vsync";
			clocks = <0xd 0x6d 0xd 0x6e 0xd 0x73>;
			compatible = "qcom,mdss";
			interrupt-controller;
			interrupts = <0x0 0x48 0x4>;
			linux,phandle = <0x52>;
			phandle = <0x52>;
			power-domains = <0xd 0x2>;
			ranges;
			reg = <0x1a00000 0x1000 0x1ac8000 0x3000>;
			reg-names = "mdss_phys", "vbif_phys";
			status = "okay";

			dsi-phy@1a98300 {
				#clock-cells = <0x1>;
				#phy-cells = <0x0>;
				clock-names = "iface";
				clocks = <0xd 0x6d>;
				compatible = "qcom,dsi-phy-28nm-lp";
				linux,phandle = <0x55>;
				phandle = <0x55>;
				reg = <0x1a98300 0xd4 0x1a98500 0x280 0x1a98780 0x30>;
				reg-names = "dsi_pll", "dsi_phy", "dsi_phy_regulator";
				status = "okay";
				vddio-supply = <0x28>;
			};

			dsi@1a98000 {
				assigned-clock-parents = <0x55 0x0 0x55 0x1>;
				assigned-clocks = <0xd 0x2b 0xd 0x2e>;
				clock-names = "mdp_core", "iface", "bus", "byte", "pixel", "core";
				clocks = <0xd 0x71 0xd 0x6d 0xd 0x6e 0xd 0x6f 0xd 0x72 0xd 0x70>;
				compatible = "qcom,mdss-dsi-ctrl";
				interrupt-parent = <0x52>;
				interrupts = <0x4 0x0>;
				linux,phandle = <0xae>;
				phandle = <0xae>;
				phy-names = "dsi-phy";
				phys = <0x55>;
				reg = <0x1a98000 0x25c>;
				reg-names = "dsi_ctrl";
				status = "okay";
				vdda-supply = <0x56>;
				vddio-supply = <0x28>;

				ports {
					#address-cells = <0x1>;
					#size-cells = <0x0>;

					port@0 {
						reg = <0x0>;

						endpoint {
							linux,phandle = <0x54>;
							phandle = <0x54>;
							remote-endpoint = <0x57>;
						};
					};

					port@1 {
						reg = <0x1>;

						endpoint {
							data-lanes = <0x0 0x1 0x2 0x3>;
							linux,phandle = <0x2e>;
							phandle = <0x2e>;
							remote-endpoint = <0x58>;
						};
					};
				};
			};

			mdp@1a01000 {
				clock-names = "iface", "bus", "core", "vsync";
				clocks = <0xd 0x6d 0xd 0x6e 0xd 0x71 0xd 0x73>;
				compatible = "qcom,mdp5";
				interrupt-parent = <0x52>;
				interrupts = <0x0 0x0>;
				iommus = <0x53 0x4>;
				linux,phandle = <0xad>;
				phandle = <0xad>;
				reg = <0x1a01000 0x89000>;
				reg-names = "mdp_phys";
				status = "okay";

				ports {
					#address-cells = <0x1>;
					#size-cells = <0x0>;

					port@0 {
						reg = <0x0>;

						endpoint {
							linux,phandle = <0x57>;
							phandle = <0x57>;
							remote-endpoint = <0x54>;
						};
					};
				};
			};
		};

		memory@60000 {
			compatible = "qcom,rpm-msg-ram";
			linux,phandle = <0xb>;
			phandle = <0xb>;
			reg = <0x60000 0x8000>;
		};

		pinctrl@1000000 {
			#gpio-cells = <0x2>;
			#interrupt-cells = <0x2>;
			compatible = "qcom,msm8916-pinctrl";
			gpio-controller;
			gpio-line-names = "[UART0_TX]", "[UART0_RX]", "[UART0_CTS_N]", "[UART0_RTS_N]", "[UART1_TX]", "[UART1_RX]", "[I2C0_SDA]", "[I2C0_SCL]", "[SPI1_DOUT]", "[SPI1_DIN]", "[SPI1_CS]", "[SPI1_SCLK]", "GPIO-B", "GPIO-C", "[I2C3_SDA]", "[I2C3_SCL]", "[SPI0_MOSI]", "[SPI0_MISO]", "[SPI0_CS_N]", "[SPI0_CLK]", "HDMI_HPD_N", "USR_LED_1_CTRL", "[I2C1_SDA]", "[I2C1_SCL]", "GPIO-G", "GPIO-H", "[CSI0_MCLK]", "[CSI1_MCLK]", "GPIO-K", "[I2C2_SDA]", "[I2C2_SCL]", "DSI2HDMI_INT_N", "DSI_SW_SEL_APQ", "GPIO-L", "GPIO-J", "GPIO-I", "GPIO-A", "FORCED_USB_BOOT", "SD_CARD_DET_N", "[WCSS_BT_SSBI]", "[WCSS_WLAN_DATA_2]", "[WCSS_WLAN_DATA_1]", "[WCSS_WLAN_DATA_0]", "[WCSS_WLAN_SET]", "[WCSS_WLAN_CLK]", "[WCSS_FM_SSBI]", "[WCSS_FM_SDI]", "[WCSS_BT_DAT_CTL]", "[WCSS_BT_DAT_STB]", "NC", "NC", "NC", "NC", "NC", "NC", "NC", "NC", "NC", "NC", "NC", "NC", "NC", "NC", "[CDC_PDM0_CLK]", "[CDC_PDM0_SYNC]", "[CDC_PDM0_TX0]", "[CDC_PDM0_RX0]", "[CDC_PDM0_RX1]", "[CDC_PDM0_RX2]", "GPIO-D", "NC", "NC", "NC", "NC", "NC", "NC", "NC", "NC", "NC", "NC", "BOOT_CONFIG_0", "BOOT_CONFIG_1", "BOOT_CONFIG_2", "BOOT_CONFIG_3", "NC", "NC", "BOOT_CONFIG_5", "NC", "NC", "NC", "NC", "NC", "NC", "NC", "NC", "NC", "NC", "NC", "NC", "NC", "NC", "NC", "NC", "NC", "SSBI_GPS", "NC", "NC", "KEY_VOLP_N", "NC", "NC", "[LS_EXP_MI2S_WS]", "NC", "NC", "[LS_EXP_MI2S_SCK]", "[LS_EXP_MI2S_DATA0]", "GPIO-E", "NC", "[DSI2HDMI_MI2S_WS]", "[DSI2HDMI_MI2S_SCK]", "[DSI2HDMI_MI2S_DATA0]", "USR_LED_2_CTRL", "SB_HS_ID";
			interrupt-controller;
			interrupts = <0x0 0xd0 0x4>;
			linux,phandle = <0x26>;
			phandle = <0x26>;
			reg = <0x1000000 0x300000>;

			adv533_int_active {
				linux,phandle = <0x2a>;
				phandle = <0x2a>;

				pinconf {
					bias-disable;
					drive-strength = <0x10>;
					pins = "gpio31";
				};

				pinmux {
					function = "gpio";
					pins = "gpio31";
				};
			};

			adv7533_int_suspend {
				linux,phandle = <0x2c>;
				phandle = <0x2c>;

				pinconf {
					bias-disable;
					drive-strength = <0x2>;
					pins = "gpio31";
				};

				pinmux {
					function = "gpio";
					pins = "gpio31";
				};
			};

			adv7533_switch_active {
				linux,phandle = <0x2b>;
				phandle = <0x2b>;

				pinconf {
					bias-disable;
					drive-strength = <0x10>;
					pins = "gpio32";
				};

				pinmux {
					function = "gpio";
					pins = "gpio32";
				};
			};

			adv7533_switch_suspend {
				linux,phandle = <0x2d>;
				phandle = <0x2d>;

				pinconf {
					bias-disable;
					drive-strength = <0x2>;
					pins = "gpio32";
				};

				pinmux {
					function = "gpio";
					pins = "gpio32";
				};
			};

			blsp1_uart1_default {
				linux,phandle = <0x11>;
				phandle = <0x11>;

				pinconf {
					bias-disable;
					drive-strength = <0x10>;
					pins = "gpio0", "gpio1", "gpio2", "gpio3";
				};

				pinmux {
					function = "blsp_uart1";
					pins = "gpio0", "gpio1", "gpio2", "gpio3";
				};
			};

			blsp1_uart1_sleep {
				linux,phandle = <0x12>;
				phandle = <0x12>;

				pinconf {
					bias-pull-down;
					drive-strength = <0x2>;
					pins = "gpio0", "gpio1", "gpio2", "gpio3";
				};

				pinmux {
					function = "gpio";
					pins = "gpio0", "gpio1", "gpio2", "gpio3";
				};
			};

			blsp1_uart2_default {
				linux,phandle = <0x14>;
				phandle = <0x14>;

				pinconf {
					bias-disable;
					drive-strength = <0x10>;
					pins = "gpio4", "gpio5";
				};

				pinmux {
					function = "blsp_uart2";
					pins = "gpio4", "gpio5";
				};
			};

			blsp1_uart2_sleep {
				linux,phandle = <0x15>;
				phandle = <0x15>;

				pinconf {
					bias-pull-down;
					drive-strength = <0x2>;
					pins = "gpio4", "gpio5";
				};

				pinmux {
					function = "gpio";
					pins = "gpio4", "gpio5";
				};
			};

			cdc-dmic-lines {

				dmic_lines_off {
					linux,phandle = <0x9a>;
					phandle = <0x9a>;

					pinconf {
						bias-disable;
						drive-strength = <0x2>;
						pins = "gpio0", "gpio1";
					};

					pinmux_dmic0_clk {
						function = "dmic0_clk";
						pins = "gpio0";
					};

					pinmux_dmic0_data {
						function = "dmic0_data";
						pins = "gpio1";
					};
				};

				dmic_lines_on {
					linux,phandle = <0x99>;
					phandle = <0x99>;

					pinconf {
						drive-strength = <0x8>;
						pins = "gpio0", "gpio1";
					};

					pinmux_dmic0_clk {
						function = "dmic0_clk";
						pins = "gpio0";
					};

					pinmux_dmic0_data {
						function = "dmic0_data";
						pins = "gpio1";
					};
				};
			};

			cdc-pdm-lines {

				pdm_lines_off {
					linux,phandle = <0x86>;
					phandle = <0x86>;

					pinconf {
						bias-disable;
						drive-strength = <0x2>;
						pins = "gpio63", "gpio64", "gpio65", "gpio66", "gpio67", "gpio68";
					};

					pinmux {
						function = "cdc_pdm0";
						pins = "gpio63", "gpio64", "gpio65", "gpio66", "gpio67", "gpio68";
					};
				};

				pdm_lines_on {
					linux,phandle = <0x83>;
					phandle = <0x83>;

					pinconf {
						bias-pull-none;
						drive-strength = <0x8>;
						pins = "gpio63", "gpio64", "gpio65", "gpio66", "gpio67", "gpio68";
					};

					pinmux {
						function = "cdc_pdm0";
						pins = "gpio63", "gpio64", "gpio65", "gpio66", "gpio67", "gpio68";
					};
				};
			};

			ext-mclk-tlmm-lines {

				mclk_lines_off {
					linux,phandle = <0x88>;
					phandle = <0x88>;

					pinconf {
						bias-disable;
						drive-strength = <0x2>;
						pins = "gpio116";
					};

					pinmux {
						function = "pri_mi2s";
						pins = "gpio116";
					};
				};

				mclk_lines_on {
					linux,phandle = <0x85>;
					phandle = <0x85>;

					pinconf {
						bias-pull-none;
						drive-strength = <0x8>;
						pins = "gpio116";
					};

					pinmux {
						function = "pri_mi2s";
						pins = "gpio116";
					};
				};
			};

			ext-pri-tlmm-lines {

				ext_pa_off {
					linux,phandle = <0x96>;
					phandle = <0x96>;

					pinconf {
						bias-disable;
						drive-strength = <0x2>;
						pins = "gpio113", "gpio114", "gpio115", "gpio116";
					};

					pinmux {
						function = "pri_mi2s";
						pins = "gpio113", "gpio114", "gpio115", "gpio116";
					};
				};

				ext_pa_on {
					linux,phandle = <0x95>;
					phandle = <0x95>;

					pinconf {
						bias-pull-none;
						drive-strength = <0x8>;
						pins = "gpio113", "gpio114", "gpio115", "gpio116";
					};

					pinmux {
						function = "pri_mi2s";
						pins = "gpio113", "gpio114", "gpio115", "gpio116";
					};
				};
			};

			ext-pri-ws-line {

				ext_pa_off {
					linux,phandle = <0x98>;
					phandle = <0x98>;

					pinconf {
						bias-disable;
						drive-strength = <0x2>;
						pins = "gpio110";
					};

					pinmux {
						function = "pri_mi2s_ws";
						pins = "gpio110";
					};
				};

				ext_pa_on {
					linux,phandle = <0x97>;
					phandle = <0x97>;

					pinconf {
						bias-pull-none;
						drive-strength = <0x8>;
						pins = "gpio110";
					};

					pinmux {
						function = "pri_mi2s_ws";
						pins = "gpio110";
					};
				};
			};

			ext-sec-tlmm-lines {

				tlmm_lines_off {
					linux,phandle = <0x87>;
					phandle = <0x87>;

					pinconf {
						bias-disable;
						drive-strength = <0x2>;
						pins = "gpio112", "gpio117", "gpio118", "gpio119";
					};

					pinmux {
						function = "sec_mi2s";
						pins = "gpio112", "gpio117", "gpio118", "gpio119";
					};
				};

				tlmm_lines_on {
					linux,phandle = <0x84>;
					phandle = <0x84>;

					pinconf {
						bias-pull-none;
						drive-strength = <0x8>;
						pins = "gpio112", "gpio117", "gpio118", "gpio119";
					};

					pinmux {
						function = "sec_mi2s";
						pins = "gpio112", "gpio117", "gpio118", "gpio119";
					};
				};
			};

			i2c2_default {
				linux,phandle = <0x22>;
				phandle = <0x22>;

				pinconf {
					bias-disable;
					drive-strength = <0x10>;
					pins = "gpio6", "gpio7";
				};

				pinmux {
					function = "blsp_i2c2";
					pins = "gpio6", "gpio7";
				};
			};

			i2c2_sleep {
				linux,phandle = <0x23>;
				phandle = <0x23>;

				pinconf {
					bias-disable;
					drive-strength = <0x2>;
					pins = "gpio6", "gpio7";
				};

				pinmux {
					function = "gpio";
					pins = "gpio6", "gpio7";
				};
			};

			i2c4_default {
				linux,phandle = <0x24>;
				phandle = <0x24>;

				pinconf {
					bias-disable;
					drive-strength = <0x10>;
					pins = "gpio14", "gpio15";
				};

				pinmux {
					function = "blsp_i2c4";
					pins = "gpio14", "gpio15";
				};
			};

			i2c4_sleep {
				linux,phandle = <0x25>;
				phandle = <0x25>;

				pinconf {
					bias-disable;
					drive-strength = <0x2>;
					pins = "gpio14", "gpio15";
				};

				pinmux {
					function = "gpio";
					pins = "gpio14", "gpio15";
				};
			};

			i2c6_default {
				linux,phandle = <0x30>;
				phandle = <0x30>;

				pinconf {
					bias-disable;
					drive-strength = <0x10>;
					pins = "gpio22", "gpio23";
				};

				pinmux {
					function = "blsp_i2c6";
					pins = "gpio22", "gpio23";
				};
			};

			i2c6_sleep {
				linux,phandle = <0x31>;
				phandle = <0x31>;

				pinconf {
					bias-disable;
					drive-strength = <0x2>;
					pins = "gpio22", "gpio23";
				};

				pinmux {
					function = "gpio";
					pins = "gpio22", "gpio23";
				};
			};

			msm_key_volp_n_default {
				linux,phandle = <0x90>;
				phandle = <0x90>;

				pinconf {
					bias-pull-up;
					drive-strength = <0x8>;
					input-enable;
					pins = "gpio107";
				};

				pinmux {
					function = "gpio";
					pins = "gpio107";
				};
			};

			msmgpio_leds {
				linux,phandle = <0x7e>;
				phandle = <0x7e>;

				pinconf {
					function = "gpio";
					output-low;
					pins = "gpio21", "gpio120";
				};
			};

			pmx_sdc1_clk {

				clk_off {
					linux,phandle = <0x38>;
					phandle = <0x38>;

					pinconf {
						bias-disable;
						drive-strength = <0x2>;
						pins = "sdc1_clk";
					};

					pinmux {
						pins = "sdc1_clk";
					};
				};

				clk_on {
					linux,phandle = <0x35>;
					phandle = <0x35>;

					pinconf {
						bias-disable;
						drive-strength = <0x10>;
						pins = "sdc1_clk";
					};

					pinmux {
						pins = "sdc1_clk";
					};
				};
			};

			pmx_sdc1_cmd {

				cmd_off {
					linux,phandle = <0x39>;
					phandle = <0x39>;

					pinconf {
						bias-pull-up;
						drive-strength = <0x2>;
						pins = "sdc1_cmd";
					};

					pinmux {
						pins = "sdc1_cmd";
					};
				};

				cmd_on {
					linux,phandle = <0x36>;
					phandle = <0x36>;

					pinconf {
						bias-pull-up;
						drive-strength = <0xa>;
						pins = "sdc1_cmd";
					};

					pinmux {
						pins = "sdc1_cmd";
					};
				};
			};

			pmx_sdc1_data {

				data_off {
					linux,phandle = <0x3a>;
					phandle = <0x3a>;

					pinconf {
						bias-pull-up;
						drive-strength = <0x2>;
						pins = "sdc1_data";
					};

					pinmux {
						pins = "sdc1_data";
					};
				};

				data_on {
					linux,phandle = <0x37>;
					phandle = <0x37>;

					pinconf {
						bias-pull-up;
						drive-strength = <0xa>;
						pins = "sdc1_data";
					};

					pinmux {
						pins = "sdc1_data";
					};
				};
			};

			pmx_sdc2_cd_pin {

				cd_off {
					linux,phandle = <0x44>;
					phandle = <0x44>;

					pinconf {
						bias-disable;
						drive-strength = <0x2>;
						pins = "gpio38";
					};

					pinmux {
						function = "gpio";
						pins = "gpio38";
					};
				};

				cd_on {
					linux,phandle = <0x40>;
					phandle = <0x40>;

					pinconf {
						bias-pull-up;
						drive-strength = <0x2>;
						pins = "gpio38";
					};

					pinmux {
						function = "gpio";
						pins = "gpio38";
					};
				};
			};

			pmx_sdc2_clk {

				clk_off {
					linux,phandle = <0x41>;
					phandle = <0x41>;

					pinconf {
						bias-disable;
						drive-strength = <0x2>;
						pins = "sdc2_clk";
					};

					pinmux {
						pins = "sdc2_clk";
					};
				};

				clk_on {
					linux,phandle = <0x3d>;
					phandle = <0x3d>;

					pinconf {
						bias-disable;
						drive-strength = <0x10>;
						pins = "sdc2_clk";
					};

					pinmux {
						pins = "sdc2_clk";
					};
				};
			};

			pmx_sdc2_cmd {

				cmd_off {
					linux,phandle = <0x42>;
					phandle = <0x42>;

					pinconf {
						bias-pull-up;
						drive-strength = <0x2>;
						pins = "sdc2_cmd";
					};

					pinmux {
						pins = "sdc2_cmd";
					};
				};

				cmd_on {
					linux,phandle = <0x3e>;
					phandle = <0x3e>;

					pinconf {
						bias-pull-up;
						drive-strength = <0xa>;
						pins = "sdc2_cmd";
					};

					pinmux {
						pins = "sdc2_cmd";
					};
				};
			};

			pmx_sdc2_data {

				data_off {
					linux,phandle = <0x43>;
					phandle = <0x43>;

					pinconf {
						bias-pull-up;
						drive-strength = <0x2>;
						pins = "sdc2_data";
					};

					pinmux {
						pins = "sdc2_data";
					};
				};

				data_on {
					linux,phandle = <0x3f>;
					phandle = <0x3f>;

					pinconf {
						bias-pull-up;
						drive-strength = <0xa>;
						pins = "sdc2_data";
					};

					pinmux {
						pins = "sdc2_data";
					};
				};
			};

			spi1_default {
				linux,phandle = <0x16>;
				phandle = <0x16>;

				pinconf {
					bias-disable;
					drive-strength = <0xc>;
					pins = "gpio0", "gpio1", "gpio3";
				};

				pinconf_cs {
					bias-disable;
					drive-strength = <0x10>;
					output-high;
					pins = "gpio2";
				};

				pinmux {
					function = "blsp_spi1";
					pins = "gpio0", "gpio1", "gpio3";
				};

				pinmux_cs {
					function = "gpio";
					pins = "gpio2";
				};
			};

			spi1_sleep {
				linux,phandle = <0x17>;
				phandle = <0x17>;

				pinconf {
					bias-pull-down;
					drive-strength = <0x2>;
					pins = "gpio0", "gpio1", "gpio2", "gpio3";
				};

				pinmux {
					function = "gpio";
					pins = "gpio0", "gpio1", "gpio2", "gpio3";
				};
			};

			spi2_default {
				linux,phandle = <0x18>;
				phandle = <0x18>;

				pinconf {
					bias-disable;
					drive-strength = <0xc>;
					pins = "gpio4", "gpio5", "gpio7";
				};

				pinconf_cs {
					bias-disable;
					drive-strength = <0x10>;
					output-high;
					pins = "gpio6";
				};

				pinmux {
					function = "blsp_spi2";
					pins = "gpio4", "gpio5", "gpio7";
				};

				pinmux_cs {
					function = "gpio";
					pins = "gpio6";
				};
			};

			spi2_sleep {
				linux,phandle = <0x19>;
				phandle = <0x19>;

				pinconf {
					bias-pull-down;
					drive-strength = <0x2>;
					pins = "gpio4", "gpio5", "gpio6", "gpio7";
				};

				pinmux {
					function = "gpio";
					pins = "gpio4", "gpio5", "gpio6", "gpio7";
				};
			};

			spi3_default {
				linux,phandle = <0x1a>;
				phandle = <0x1a>;

				pinconf {
					bias-disable;
					drive-strength = <0xc>;
					pins = "gpio8", "gpio9", "gpio11";
				};

				pinconf_cs {
					bias-disable;
					drive-strength = <0x10>;
					output-high;
					pins = "gpio10";
				};

				pinmux {
					function = "blsp_spi3";
					pins = "gpio8", "gpio9", "gpio11";
				};

				pinmux_cs {
					function = "gpio";
					pins = "gpio10";
				};
			};

			spi3_sleep {
				linux,phandle = <0x1b>;
				phandle = <0x1b>;

				pinconf {
					bias-pull-down;
					drive-strength = <0x2>;
					pins = "gpio8", "gpio9", "gpio10", "gpio11";
				};

				pinmux {
					function = "gpio";
					pins = "gpio8", "gpio9", "gpio10", "gpio11";
				};
			};

			spi4_default {
				linux,phandle = <0x1c>;
				phandle = <0x1c>;

				pinconf {
					bias-disable;
					drive-strength = <0xc>;
					pins = "gpio12", "gpio13", "gpio15";
				};

				pinconf_cs {
					bias-disable;
					drive-strength = <0x10>;
					output-high;
					pins = "gpio14";
				};

				pinmux {
					function = "blsp_spi4";
					pins = "gpio12", "gpio13", "gpio15";
				};

				pinmux_cs {
					function = "gpio";
					pins = "gpio14";
				};
			};

			spi4_sleep {
				linux,phandle = <0x1d>;
				phandle = <0x1d>;

				pinconf {
					bias-pull-down;
					drive-strength = <0x2>;
					pins = "gpio12", "gpio13", "gpio14", "gpio15";
				};

				pinmux {
					function = "gpio";
					pins = "gpio12", "gpio13", "gpio14", "gpio15";
				};
			};

			spi5_default {
				linux,phandle = <0x1e>;
				phandle = <0x1e>;

				pinconf {
					bias-disable;
					drive-strength = <0xc>;
					pins = "gpio16", "gpio17", "gpio19";
				};

				pinconf_cs {
					bias-disable;
					drive-strength = <0x10>;
					output-high;
					pins = "gpio18";
				};

				pinmux {
					function = "blsp_spi5";
					pins = "gpio16", "gpio17", "gpio19";
				};

				pinmux_cs {
					function = "gpio";
					pins = "gpio18";
				};
			};

			spi5_sleep {
				linux,phandle = <0x1f>;
				phandle = <0x1f>;

				pinconf {
					bias-pull-down;
					drive-strength = <0x2>;
					pins = "gpio16", "gpio17", "gpio18", "gpio19";
				};

				pinmux {
					function = "gpio";
					pins = "gpio16", "gpio17", "gpio18", "gpio19";
				};
			};

			spi6_default {
				linux,phandle = <0x20>;
				phandle = <0x20>;

				pinconf {
					bias-disable;
					drive-strength = <0xc>;
					pins = "gpio20", "gpio21", "gpio23";
				};

				pinconf_cs {
					bias-disable;
					drive-strength = <0x10>;
					output-high;
					pins = "gpio22";
				};

				pinmux {
					function = "blsp_spi6";
					pins = "gpio20", "gpio21", "gpio23";
				};

				pinmux_cs {
					function = "gpio";
					pins = "gpio22";
				};
			};

			spi6_sleep {
				linux,phandle = <0x21>;
				phandle = <0x21>;

				pinconf {
					bias-pull-down;
					drive-strength = <0x2>;
					pins = "gpio20", "gpio21", "gpio22", "gpio23";
				};

				pinmux {
					function = "gpio";
					pins = "gpio20", "gpio21", "gpio22", "gpio23";
				};
			};

			usb-id-default {
				linux,phandle = <0x8e>;
				phandle = <0x8e>;

				pinconf {
					bias-pull-up;
					drive-strength = <0x8>;
					input-enable;
					pins = "gpio121";
				};

				pinmux {
					function = "gpio";
					pins = "gpio121";
				};
			};

			wcnss-active {
				linux,phandle = <0x63>;
				phandle = <0x63>;

				pinconf {
					bias-pull-up;
					drive-strength = <0x6>;
					pins = "gpio40", "gpio41", "gpio42", "gpio43", "gpio44";
				};

				pinmux {
					function = "wcss_wlan";
					pins = "gpio40", "gpio41", "gpio42", "gpio43", "gpio44";
				};
			};
		};

		qfprom@5c000 {
			#address-cells = <0x1>;
			#size-cells = <0x1>;
			compatible = "qcom,qfprom";
			linux,phandle = <0xac>;
			phandle = <0xac>;
			reg = <0x5c000 0x1000>;

			caldata@d0 {
				linux,phandle = <0x4e>;
				phandle = <0x4e>;
				reg = <0xd0 0x8>;
			};

			calsel@ec {
				linux,phandle = <0x4f>;
				phandle = <0x4f>;
				reg = <0xec 0x4>;
			};
		};

		replicator@824000 {
			clock-names = "apb_pclk", "atclk";
			clocks = <0x27 0x8 0x27 0x9>;
			compatible = "arm,coresight-dynamic-replicator", "arm,primecell";
			reg = <0x824000 0x1000>;

			ports {
				#address-cells = <0x1>;
				#size-cells = <0x0>;

				port@0 {
					reg = <0x0>;

					endpoint {
						linux,phandle = <0x70>;
						phandle = <0x70>;
						remote-endpoint = <0x6b>;
					};
				};

				port@1 {
					reg = <0x1>;

					endpoint {
						linux,phandle = <0x68>;
						phandle = <0x68>;
						remote-endpoint = <0x6c>;
					};
				};

				port@2 {
					reg = <0x0>;

					endpoint {
						linux,phandle = <0x6f>;
						phandle = <0x6f>;
						remote-endpoint = <0x6d>;
						slave-mode;
					};
				};
			};
		};

		restart@4ab000 {
			compatible = "qcom,pshold";
			reg = <0x4ab000 0x4>;
		};

		rng@22000 {
			clock-names = "core";
			clocks = <0xd 0x79>;
			compatible = "qcom,prng";
			reg = <0x22000 0x200>;
		};

		sdhci@7824000 {
			bus-width = <0x8>;
			clock-names = "core", "iface", "xo";
			clocks = <0xd 0x7b 0xd 0x7a 0x32>;
			compatible = "qcom,sdhci-msm-v4";
			interrupt-names = "hc_irq", "pwr_irq";
			interrupts = <0x0 0x7b 0x4 0x0 0x8a 0x4>;
			linux,phandle = <0xa6>;
			mmc-ddr-1_8v;
			non-removable;
			phandle = <0xa6>;
			pinctrl-0 = <0x35 0x36 0x37>;
			pinctrl-1 = <0x38 0x39 0x3a>;
			pinctrl-names = "default", "sleep";
			reg = <0x7824900 0x11c 0x7824000 0x800>;
			reg-names = "hc_mem", "core_mem";
			status = "okay";
			vmmc-supply = <0x33>;
			vqmmc-supply = <0x34>;
		};

		sdhci@7864000 {
			bus-width = <0x4>;
			cd-gpios = <0x26 0x26 0x1>;
			clock-names = "core", "iface", "xo";
			clocks = <0xd 0x7d 0xd 0x7c 0x32>;
			compatible = "qcom,sdhci-msm-v4";
			interrupt-names = "hc_irq", "pwr_irq";
			interrupts = <0x0 0x7d 0x4 0x0 0xdd 0x4>;
			linux,phandle = <0xa7>;
			phandle = <0xa7>;
			pinctrl-0 = <0x3d 0x3e 0x3f 0x40>;
			pinctrl-1 = <0x41 0x42 0x43 0x44>;
			pinctrl-names = "default", "sleep";
			reg = <0x7864900 0x11c 0x7864000 0x800>;
			reg-names = "hc_mem", "core_mem";
			status = "okay";
			vmmc-supply = <0x3b>;
			vqmmc-supply = <0x3c>;
		};

		serial@78af000 {
			clock-names = "core", "iface";
			clocks = <0xd 0x44 0xd 0x36>;
			compatible = "qcom,msm-uartdm-v1.4", "qcom,msm-uartdm";
			dma-names = "rx", "tx";
			dmas = <0x10 0x1 0x10 0x0>;
			interrupts = <0x0 0x6b 0x4>;
			label = "LS-UART0";
			linux,phandle = <0x9b>;
			phandle = <0x9b>;
			pinctrl-0 = <0x11>;
			pinctrl-1 = <0x12>;
			pinctrl-names = "default", "sleep";
			reg = <0x78af000 0x200>;
			status = "okay";
		};

		serial@78b0000 {
			clock-names = "core", "iface";
			clocks = <0xd 0x45 0xd 0x36>;
			compatible = "qcom,msm-uartdm-v1.4", "qcom,msm-uartdm";
			dma-names = "rx", "tx";
			dmas = <0x10 0x3 0x10 0x2>;
			interrupts = <0x0 0x6c 0x4>;
			label = "LS-UART1";
			linux,phandle = <0x9c>;
			phandle = <0x9c>;
			pinctrl-0 = <0x14>;
			pinctrl-1 = <0x15>;
			pinctrl-names = "default", "sleep";
			reg = <0x78b0000 0x200>;
			status = "okay";
		};

		sound {
			compatible = "qcom,apq8016-sbc-sndcard";
			linux,phandle = <0xb0>;
			phandle = <0xb0>;
			pinctrl-0 = <0x83 0x84 0x85>;
			pinctrl-1 = <0x86 0x87 0x88>;
			pinctrl-names = "default", "sleep";
			qcom,audio-routing = "AMIC2", "MIC BIAS Internal2", "AMIC3", "MIC BIAS External1";
			qcom,model = "DB410c";
			reg = <0x7702000 0x4 0x7702004 0x4>;
			reg-names = "mic-iomux", "spkr-iomux";
			status = "okay";

			external-dai-link@0 {
				link-name = "ADV7533";

				codec {
					sound-dai = <0x8a 0x0>;
				};

				cpu {
					sound-dai = <0x89 0x3>;
				};
			};

			internal-codec-capture-dai-link@0 {
				link-name = "WCD-Capture";

				codec {
					sound-dai = <0x8b 0x1 0x8c 0x1>;
				};

				cpu {
					sound-dai = <0x89 0x2>;
				};
			};

			internal-codec-playback-dai-link@0 {
				link-name = "WCD";

				codec {
					sound-dai = <0x8b 0x0 0x8c 0x0>;
				};

				cpu {
					sound-dai = <0x89 0x0>;
				};
			};
		};

		spi@78b5000 {
			#address-cells = <0x1>;
			#size-cells = <0x0>;
			clock-names = "core", "iface";
			clocks = <0xd 0x39 0xd 0x36>;
			compatible = "qcom,spi-qup-v2.2.1";
			dma-names = "rx", "tx";
			dmas = <0x10 0x5 0x10 0x4>;
			interrupts = <0x0 0x5f 0x4>;
			linux,phandle = <0x9d>;
			phandle = <0x9d>;
			pinctrl-0 = <0x16>;
			pinctrl-1 = <0x17>;
			pinctrl-names = "default", "sleep";
			reg = <0x78b5000 0x500>;
			status = "disabled";
		};

		spi@78b6000 {
			#address-cells = <0x1>;
			#size-cells = <0x0>;
			clock-names = "core", "iface";
			clocks = <0xd 0x3b 0xd 0x36>;
			compatible = "qcom,spi-qup-v2.2.1";
			dma-names = "rx", "tx";
			dmas = <0x10 0x7 0x10 0x6>;
			interrupts = <0x0 0x60 0x4>;
			linux,phandle = <0x9e>;
			phandle = <0x9e>;
			pinctrl-0 = <0x18>;
			pinctrl-1 = <0x19>;
			pinctrl-names = "default", "sleep";
			reg = <0x78b6000 0x500>;
			status = "disabled";
		};

		spi@78b7000 {
			#address-cells = <0x1>;
			#size-cells = <0x0>;
			clock-names = "core", "iface";
			clocks = <0xd 0x3d 0xd 0x36>;
			compatible = "qcom,spi-qup-v2.2.1";
			dma-names = "rx", "tx";
			dmas = <0x10 0x9 0x10 0x8>;
			interrupts = <0x0 0x61 0x4>;
			label = "HS-SPI1";
			linux,phandle = <0x9f>;
			phandle = <0x9f>;
			pinctrl-0 = <0x1a>;
			pinctrl-1 = <0x1b>;
			pinctrl-names = "default", "sleep";
			reg = <0x78b7000 0x500>;
			status = "okay";
		};

		spi@78b8000 {
			#address-cells = <0x1>;
			#size-cells = <0x0>;
			clock-names = "core", "iface";
			clocks = <0xd 0x3f 0xd 0x36>;
			compatible = "qcom,spi-qup-v2.2.1";
			dma-names = "rx", "tx";
			dmas = <0x10 0xb 0x10 0xa>;
			interrupts = <0x0 0x62 0x4>;
			linux,phandle = <0xa0>;
			phandle = <0xa0>;
			pinctrl-0 = <0x1c>;
			pinctrl-1 = <0x1d>;
			pinctrl-names = "default", "sleep";
			reg = <0x78b8000 0x500>;
			status = "disabled";
		};

		spi@78b9000 {
			#address-cells = <0x1>;
			#size-cells = <0x0>;
			clock-names = "core", "iface";
			clocks = <0xd 0x41 0xd 0x36>;
			compatible = "qcom,spi-qup-v2.2.1";
			dma-names = "rx", "tx";
			dmas = <0x10 0xd 0x10 0xc>;
			interrupts = <0x0 0x63 0x4>;
			label = "LS-SPI0";
			linux,phandle = <0xa1>;
			phandle = <0xa1>;
			pinctrl-0 = <0x1e>;
			pinctrl-1 = <0x1f>;
			pinctrl-names = "default", "sleep";
			reg = <0x78b9000 0x500>;
			status = "okay";
		};

		spi@78ba000 {
			#address-cells = <0x1>;
			#size-cells = <0x0>;
			clock-names = "core", "iface";
			clocks = <0xd 0x43 0xd 0x36>;
			compatible = "qcom,spi-qup-v2.2.1";
			dma-names = "rx", "tx";
			dmas = <0x10 0xf 0x10 0xe>;
			interrupts = <0x0 0x64 0x4>;
			linux,phandle = <0xa2>;
			phandle = <0xa2>;
			pinctrl-0 = <0x20>;
			pinctrl-1 = <0x21>;
			pinctrl-names = "default", "sleep";
			reg = <0x78ba000 0x500>;
			status = "disabled";
		};

		spmi@200f000 {
			#address-cells = <0x2>;
			#interrupt-cells = <0x4>;
			#size-cells = <0x0>;
			compatible = "qcom,spmi-pmic-arb";
			interrupt-controller;
			interrupt-names = "periph_irq";
			interrupts = <0x0 0xbe 0x4>;
			linux,phandle = <0x4d>;
			phandle = <0x4d>;
			qcom,channel = <0x0>;
			qcom,ee = <0x0>;
			reg = <0x200f000 0x1000 0x2400000 0x400000 0x2c00000 0x400000 0x3800000 0x200000 0x200a000 0x2100>;
			reg-names = "core", "chnls", "obsrvr", "intr", "cnfg";

			pm8916@0 {
				#address-cells = <0x1>;
				#size-cells = <0x0>;
				compatible = "qcom,pm8916", "qcom,spmi-pmic";
				linux,phandle = <0xa8>;
				phandle = <0xa8>;
				reg = <0x0 0x0>;

				gpios@c000 {
					#gpio-cells = <0x2>;
					compatible = "qcom,pm8916-gpio";
					gpio-controller;
					gpio-line-names = "USR_LED_3_CTRL", "USR_LED_4_CTRL", "USB_HUB_RESET_N_PM", "USB_SW_SEL_PM";
					interrupts = <0x0 0xc0 0x0 0x0 0x0 0xc1 0x0 0x0 0x0 0xc2 0x0 0x0 0x0 0xc3 0x0 0x0>;
					linux,phandle = <0x81>;
					phandle = <0x81>;
					reg = <0xc000>;

					pm8916_gpios_leds {
						linux,phandle = <0x7f>;
						phandle = <0x7f>;

						pinconf {
							function = "normal";
							output-low;
							pins = "gpio1", "gpio2";
						};
					};

					usb_hub_reset_pm {
						linux,phandle = <0xa9>;
						phandle = <0xa9>;

						pinconf {
							function = "normal";
							output-low;
							pins = "gpio3";
						};
					};

					usb_sw_sel_pm {
						linux,phandle = <0x47>;
						phandle = <0x47>;

						pinconf {
							function = "normal";
							input-disable;
							output-high;
							pins = "gpio4";
							power-source = <0x0>;
						};
					};
				};

				mpps@a000 {
					#gpio-cells = <0x2>;
					compatible = "qcom,pm8916-mpp";
					gpio-controller;
					gpio-line-names = "VDD_PX_BIAS", "WLAN_LED_CTRL", "BT_LED_CTRL", "GPIO-F";
					interrupts = <0x0 0xa0 0x0 0x0 0x0 0xa1 0x0 0x0 0x0 0xa2 0x0 0x0 0x0 0xa3 0x0 0x0>;
					linux,phandle = <0x82>;
					phandle = <0x82>;
					pinctrl-0 = <0x4b>;
					pinctrl-names = "default";
					reg = <0xa000>;

					pm8916_mpp4 {
						linux,phandle = <0x4b>;
						phandle = <0x4b>;

						pinconf {
							function = "digital";
							output-low;
							pins = "mpp4";
							power-source = <0x3>;
						};
					};

					pm8916_mpps_leds {
						linux,phandle = <0x80>;
						phandle = <0x80>;

						pinconf {
							function = "digital";
							output-low;
							pins = "mpp2", "mpp3";
						};
					};
				};

				pwrkey@800 {
					bias-pull-up;
					compatible = "qcom,pm8941-pwrkey";
					debounce = <0x3d09>;
					interrupts = <0x0 0x8 0x0 0x3>;
					reg = <0x800>;
				};

				rtc@6000 {
					compatible = "qcom,pm8941-rtc";
					interrupts = <0x0 0x61 0x1 0x1>;
					reg = <0x6000>;
					reg-names = "rtc", "alarm";
				};

				temp-alarm@2400 {
					#thermal-sensor-cells = <0x0>;
					compatible = "qcom,spmi-temp-alarm";
					interrupts = <0x0 0x24 0x0 0x1>;
					io-channel-names = "thermal";
					io-channels = <0x4c 0x8>;
					linux,phandle = <0xaa>;
					phandle = <0xaa>;
					reg = <0x2400>;
				};

				vadc@3100 {
					#address-cells = <0x1>;
					#io-channel-cells = <0x1>;
					#size-cells = <0x0>;
					compatible = "qcom,spmi-vadc";
					interrupts = <0x0 0x31 0x0 0x1>;
					linux,phandle = <0x4c>;
					phandle = <0x4c>;
					reg = <0x3100>;

					die_temp {
						reg = <0x8>;
					};

					ref_1250v {
						reg = <0xa>;
					};

					ref_625mv {
						reg = <0x9>;
					};

					ref_gnd {
						reg = <0xe>;
					};

					ref_vdd {
						reg = <0xf>;
					};

					usb_in {
						qcom,pre-scaling = <0x1 0xa>;
						reg = <0x0>;
					};

					vph_pwr {
						qcom,pre-scaling = <0x1 0x3>;
						reg = <0x7>;
					};
				};
			};

			pm8916@1 {
				#address-cells = <0x1>;
				#size-cells = <0x0>;
				compatible = "qcom,pm8916", "qcom,spmi-pmic";
				linux,phandle = <0xab>;
				phandle = <0xab>;
				reg = <0x1 0x0>;

				codec@f000 {
					#sound-dai-cells = <0x1>;
					clock-names = "mclk";
					clocks = <0xd 0x9f>;
					compatible = "qcom,pm8916-wcd-analog-codec";
					interrupt-names = "cdc_spk_cnp_int", "cdc_spk_clip_int", "cdc_spk_ocp_int", "mbhc_ins_rem_det1", "mbhc_but_rel_det", "mbhc_but_press_det", "mbhc_ins_rem_det", "mbhc_switch_int", "cdc_ear_ocp_int", "cdc_hphr_ocp_int", "cdc_hphl_ocp_det", "cdc_ear_cnp_int", "cdc_hphr_cnp_int", "cdc_hphl_cnp_int";
					interrupt-parent = <0x4d>;
					interrupts = <0x1 0xf0 0x0 0x0 0x1 0xf0 0x1 0x0 0x1 0xf0 0x2 0x0 0x1 0xf0 0x3 0x0 0x1 0xf0 0x4 0x0 0x1 0xf0 0x5 0x0 0x1 0xf0 0x6 0x0 0x1 0xf0 0x7 0x0 0x1 0xf1 0x0 0x0 0x1 0xf1 0x1 0x0 0x1 0xf1 0x2 0x0 0x1 0xf1 0x3 0x0 0x1 0xf1 0x4 0x0 0x1 0xf1 0x5 0x0>;
					linux,phandle = <0x8c>;
					phandle = <0x8c>;
					qcom,mbhc-vthreshold-high = <0x4b 0x96 0xed 0x1c2 0x1f4>;
					qcom,mbhc-vthreshold-low = <0x4b 0x96 0xed 0x1c2 0x1f4>;
					reg = <0xf000 0x200>;
					reg-names = "pmic-codec-core";
					status = "okay";
					vdd-cdc-io-supply = <0x34>;
					vdd-cdc-tx-rx-cx-supply = <0x34>;
					vdd-micbias-supply = <0x4a>;
				};
			};
		};

		syscon@1905000 {
			compatible = "syscon";
			linux,phandle = <0xf>;
			phandle = <0xf>;
			reg = <0x1905000 0x20000>;
		};

		syscon@1937000 {
			compatible = "qcom,tcsr-msm8916", "syscon";
			linux,phandle = <0xe>;
			phandle = <0xe>;
			reg = <0x1937000 0x30000>;
		};

		thermal-sensor@4a8000 {
			#thermal-sensor-cells = <0x1>;
			compatible = "qcom,msm8916-tsens";
			linux,phandle = <0x6>;
			nvmem-cell-names = "calib", "calib_sel";
			nvmem-cells = <0x4e 0x4f>;
			phandle = <0x6>;
			reg = <0x4a8000 0x2000>;
		};

		timer@b020000 {
			#address-cells = <0x1>;
			#size-cells = <0x1>;
			clock-frequency = <0x124f800>;
			compatible = "arm,armv7-timer-mem";
			ranges;
			reg = <0xb020000 0x1000>;

			frame@b021000 {
				frame-number = <0x0>;
				interrupts = <0x0 0x8 0x4 0x0 0x7 0x4>;
				reg = <0xb021000 0x1000 0xb022000 0x1000>;
			};

			frame@b023000 {
				frame-number = <0x1>;
				interrupts = <0x0 0x9 0x4>;
				reg = <0xb023000 0x1000>;
				status = "disabled";
			};

			frame@b024000 {
				frame-number = <0x2>;
				interrupts = <0x0 0xa 0x4>;
				reg = <0xb024000 0x1000>;
				status = "disabled";
			};

			frame@b025000 {
				frame-number = <0x3>;
				interrupts = <0x0 0xb 0x4>;
				reg = <0xb025000 0x1000>;
				status = "disabled";
			};

			frame@b026000 {
				frame-number = <0x4>;
				interrupts = <0x0 0xc 0x4>;
				reg = <0xb026000 0x1000>;
				status = "disabled";
			};

			frame@b027000 {
				frame-number = <0x5>;
				interrupts = <0x0 0xd 0x4>;
				reg = <0xb027000 0x1000>;
				status = "disabled";
			};

			frame@b028000 {
				frame-number = <0x6>;
				interrupts = <0x0 0xe 0x4>;
				reg = <0xb028000 0x1000>;
				status = "disabled";
			};
		};

		tpiu@820000 {
			clock-names = "apb_pclk", "atclk";
			clocks = <0x27 0x8 0x27 0x9>;
			compatible = "arm,coresight-tpiu", "arm,primecell";
			reg = <0x820000 0x1000>;

			port {

				endpoint {
					linux,phandle = <0x6c>;
					phandle = <0x6c>;
					remote-endpoint = <0x68>;
					slave-mode;
				};
			};
		};

		usb@78d9000 {
			#reset-cells = <0x1>;
			adp-disable;
			ahb-burst-config = <0x0>;
			assigned-clock-rates = <0x4c4b400>;
			assigned-clocks = <0xd 0x86>;
			clock-names = "iface", "core";
			clocks = <0xd 0x85 0xd 0x86>;
			compatible = "qcom,ci-hdrc";
			dr_mode = "host";
			extcon = <0x46>;
			hnp-disable;
			interrupts = <0x0 0x86 0x4 0x0 0x8c 0x4>;
			linux,phandle = <0x48>;
			phandle = <0x48>;
			phy-names = "usb-phy";
			phy_type = "ulpi";
			phys = <0x45>;
			pinctrl-0 = <0x47>;
			pinctrl-names = "default";
			reg = <0x78d9000 0x200 0x78d9200 0x200>;
			reset-names = "core";
			resets = <0xd 0x22>;
			srp-disable;
			status = "okay";

			ulpi {

				phy {
					#phy-cells = <0x0>;
					clock-names = "ref", "sleep";
					clocks = <0x32 0xd 0x84>;
					compatible = "qcom,usb-hs-phy-msm8916", "qcom,usb-hs-phy";
					extcon = <0x46>;
					linux,phandle = <0x45>;
					phandle = <0x45>;
					qcom,init-seq = <0x44016b 0x2240313>;
					reset-names = "phy", "por";
					resets = <0xd 0x23 0x48 0x0>;
					v1p8-supply = <0x49>;
					v3p3-supply = <0x4a>;
				};
			};
		};

		video-codec@1d00000 {
			clock-names = "core", "iface", "bus";
			clocks = <0xd 0x89 0xd 0x87 0xd 0x88>;
			compatible = "qcom,msm8916-venus";
			interrupts = <0x0 0x2c 0x4>;
			iommus = <0x53 0x5>;
			linux,phandle = <0xaf>;
			memory-region = <0x7d>;
			phandle = <0xaf>;
			power-domains = <0xd 0x1>;
			reg = <0x1d00000 0xff000>;
			status = "okay";

			video-decoder {
				compatible = "venus-decoder";
			};

			video-encoder {
				compatible = "venus-encoder";
			};
		};

		wcnss@a21b000 {
			compatible = "qcom,pronto-v2-pil", "qcom,pronto";
			interrupt-names = "wdog", "fatal", "ready", "handover", "stop-ack";
			interrupts-extended = <0x1 0x0 0x95 0x1 0x61 0x0 0x1 0x61 0x1 0x1 0x61 0x2 0x1 0x61 0x3 0x1>;
			linux,phandle = <0x66>;
			memory-region = <0x60>;
			phandle = <0x66>;
			pinctrl-0 = <0x63>;
			pinctrl-names = "default";
			qcom,state = <0x62 0x0>;
			qcom,state-names = "stop";
			reg = <0xa204000 0x2000 0xa202000 0x1000 0xa21b000 0x3000>;
			reg-names = "ccu", "dxe", "pmu";
			status = "okay";
			vddmx-supply = <0x5d>;
			vddpx-supply = <0x49>;

			iris {
				clock-names = "xo";
				clocks = <0x27 0x1c>;
				compatible = "qcom,wcn3620";
				vdddig-supply = <0x34>;
				vddpa-supply = <0x65>;
				vddrfa-supply = <0x64>;
				vddxo-supply = <0x49>;
			};

			smd-edge {
				interrupts = <0x0 0x8e 0x1>;
				label = "pronto";
				qcom,ipc = <0x4 0x8 0x11>;
				qcom,remote-pid = <0x4>;
				qcom,smd-edge = <0x6>;

				wcnss {
					compatible = "qcom,wcnss";
					qcom,mmio = <0x66>;
					qcom,smd-channels = "WCNSS_CTRL";

					bt {
						compatible = "qcom,wcnss-bt";
					};

					wifi {
						compatible = "qcom,wcnss-wlan";
						interrupt-names = "tx", "rx";
						interrupts = <0x0 0x91 0x4 0x0 0x92 0x4>;
						qcom,smem-state-names = "tx-enable", "tx-rings-empty";
						qcom,smem-states = <0x67 0xa 0x67 0x9>;
					};
				};
			};
		};
	};

	thermal-zones {

		cpu-thermal0 {
			polling-delay = <0x3e8>;
			polling-delay-passive = <0xfa>;
			thermal-sensors = <0x6 0x4>;

			cooling-maps {

				map0 {
					cooling-device = <0x8 0xffffffff 0xffffffff>;
					trip = <0x7>;
				};
			};

			trips {

				trip0 {
					hysteresis = <0x7d0>;
					linux,phandle = <0x7>;
					phandle = <0x7>;
					temperature = <0x124f8>;
					type = "passive";
				};

				trip1 {
					hysteresis = <0x7d0>;
					linux,phandle = <0x91>;
					phandle = <0x91>;
					temperature = <0x1adb0>;
					type = "critical";
				};
			};
		};

		cpu-thermal1 {
			polling-delay = <0x3e8>;
			polling-delay-passive = <0xfa>;
			thermal-sensors = <0x6 0x3>;

			cooling-maps {

				map0 {
					cooling-device = <0x8 0xffffffff 0xffffffff>;
					trip = <0x9>;
				};
			};

			trips {

				trip0 {
					hysteresis = <0x7d0>;
					linux,phandle = <0x9>;
					phandle = <0x9>;
					temperature = <0x124f8>;
					type = "passive";
				};

				trip1 {
					hysteresis = <0x7d0>;
					linux,phandle = <0x92>;
					phandle = <0x92>;
					temperature = <0x1adb0>;
					type = "critical";
				};
			};
		};
	};

	timer {
		compatible = "arm,armv8-timer";
		interrupts = <0x1 0x2 0xf08 0x1 0x3 0xf08 0x1 0x4 0xf08 0x1 0x1 0xf08>;
	};

	usb-id {
		compatible = "linux,extcon-usb-gpio";
		linux,phandle = <0x46>;
		phandle = <0x46>;
		pinctrl-0 = <0x8e>;
		pinctrl-names = "default";
		vbus-gpio = <0x26 0x79 0x0>;
	};

	usb2513 {
		compatible = "smsc,usb3503";
		initial-mode = <0x1>;
		reset-gpios = <0x81 0x3 0x1>;
	};

	wcnss-smp2p {
		compatible = "qcom,smp2p";
		interrupts = <0x0 0x8f 0x1>;
		qcom,ipc = <0x4 0x8 0x12>;
		qcom,local-pid = <0x0>;
		qcom,remote-pid = <0x4>;
		qcom,smem = <0x1c3 0x1af>;

		master-kernel {
			#qcom,smem-state-cells = <0x1>;
			linux,phandle = <0x62>;
			phandle = <0x62>;
			qcom,entry-name = "master-kernel";
		};

		slave-kernel {
			#interrupt-cells = <0x2>;
			interrupt-controller;
			linux,phandle = <0x61>;
			phandle = <0x61>;
			qcom,entry-name = "slave-kernel";
		};
	};
};
